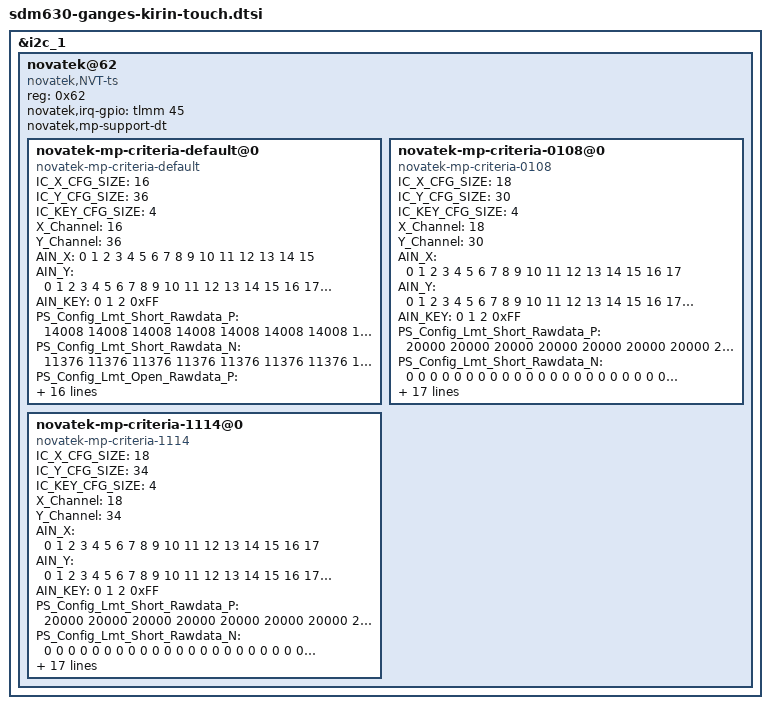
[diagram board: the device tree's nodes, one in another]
/* arch/arm64/boot/dts/somc/somc-ganges-touch.dtsi
 *
 * This program is free software; you can redistribute it and/or modify
 * it under the terms of the GNU General Public License version 2 and
 * only version 2 as published by the Free Software Foundation.
 *
 * This program is distributed in the hope that it will be useful,
 * but WITHOUT ANY WARRANTY; without even the implied warranty of
 * MERCHANTABILITY or FITNESS FOR A PARTICULAR PURPOSE.  See the
 * GNU General Public License for more details.
 */

&i2c_1 {
	status = "okay";

	novatek@62 {
		compatible = "novatek,NVT-ts";
		reg = <0x62>;
		status = "ok";

		/* vdd-supply = <&pm8994_lvs2>;    //VDDIO */
		/* avdd-supply = <&pm8994_l22>;    //VDD */

		/* novatek,reset-gpio = <&tlmm 53 0x00>; */
		novatek,irq-gpio = <&tlmm 45 0x2002>;

		/* MP */
		novatek,mp-support-dt;

		novatek-mp-criteria-default@0 {
			#address-cells = <1>;
			#size-cells = <0>;
			compatible = "novatek-mp-criteria-default";

			/* MP Config */
			IC_X_CFG_SIZE = <16>;
			IC_Y_CFG_SIZE = <36>;
			IC_KEY_CFG_SIZE = <4>;
			X_Channel = <16>;
			Y_Channel = <36>;
			AIN_X = <0 1 2 3 4 5 6 7 8 9 10 11 12 13 14 15>;
			AIN_Y = <0 1 2 3 4 5 6 7 8 9 10 11 12 13 14 15 16 17 18
				 19 20 21 22 23 24 25 26 27 28 29 30 31 32 33 34 35>;
			AIN_KEY = <0 1 2 0xFF>;

			/* MP Criteria */
			PS_Config_Lmt_Short_Rawdata_P = <
				14008 14008 14008 14008 14008 14008 14008 14008 14008 14008 14008 14008 14008 14008 14008 14008
				14008 14008 14008 14008 14008 14008 14008 14008 14008 14008 14008 14008 14008 14008 14008 14008
				14008 14008 14008 14008 14008 14008 14008 14008 14008 14008 14008 14008 14008 14008 14008 14008
				14008 14008 14008 14008 14008 14008 14008 14008 14008 14008 14008 14008 14008 14008 14008 14008
				14008 14008 14008 14008 14008 14008 14008 14008 14008 14008 14008 14008 14008 14008 14008 14008
				14008 14008 14008 14008 14008 14008 14008 14008 14008 14008 14008 14008 14008 14008 14008 14008
				14008 14008 14008 14008 14008 14008 14008 14008 14008 14008 14008 14008 14008 14008 14008 14008
				14008 14008 14008 14008 14008 14008 14008 14008 14008 14008 14008 14008 14008 14008 14008 14008
				14008 14008 14008 14008 14008 14008 14008 14008 14008 14008 14008 14008 14008 14008 14008 14008
				14008 14008 14008 14008 14008 14008 14008 14008 14008 14008 14008 14008 14008 14008 14008 14008
				14008 14008 14008 14008 14008 14008 14008 14008 14008 14008 14008 14008 14008 14008 14008 14008
				14008 14008 14008 14008 14008 14008 14008 14008 14008 14008 14008 14008 14008 14008 14008 14008
				14008 14008 14008 14008 14008 14008 14008 14008 14008 14008 14008 14008 14008 14008 14008 14008
				14008 14008 14008 14008 14008 14008 14008 14008 14008 14008 14008 14008 14008 14008 14008 14008
				14008 14008 14008 14008 14008 14008 14008 14008 14008 14008 14008 14008 14008 14008 14008 14008
				14008 14008 14008 14008 14008 14008 14008 14008 14008 14008 14008 14008 14008 14008 14008 14008
				14008 14008 14008 14008 14008 14008 14008 14008 14008 14008 14008 14008 14008 14008 14008 14008
				14008 14008 14008 14008 14008 14008 14008 14008 14008 14008 14008 14008 14008 14008 14008 14008
				14008 14008 14008 14008 14008 14008 14008 14008 14008 14008 14008 14008 14008 14008 14008 14008
				14008 14008 14008 14008 14008 14008 14008 14008 14008 14008 14008 14008 14008 14008 14008 14008
				14008 14008 14008 14008 14008 14008 14008 14008 14008 14008 14008 14008 14008 14008 14008 14008
				14008 14008 14008 14008 14008 14008 14008 14008 14008 14008 14008 14008 14008 14008 14008 14008
				14008 14008 14008 14008 14008 14008 14008 14008 14008 14008 14008 14008 14008 14008 14008 14008
				14008 14008 14008 14008 14008 14008 14008 14008 14008 14008 14008 14008 14008 14008 14008 14008
				14008 14008 14008 14008 14008 14008 14008 14008 14008 14008 14008 14008 14008 14008 14008 14008
				14008 14008 14008 14008 14008 14008 14008 14008 14008 14008 14008 14008 14008 14008 14008 14008
				14008 14008 14008 14008 14008 14008 14008 14008 14008 14008 14008 14008 14008 14008 14008 14008
				14008 14008 14008 14008 14008 14008 14008 14008 14008 14008 14008 14008 14008 14008 14008 14008
				14008 14008 14008 14008 14008 14008 14008 14008 14008 14008 14008 14008 14008 14008 14008 14008
				14008 14008 14008 14008 14008 14008 14008 14008 14008 14008 14008 14008 14008 14008 14008 14008
				14008 14008 14008 14008 14008 14008 14008 14008 14008 14008 14008 14008 14008 14008 14008 14008
				14008 14008 14008 14008 14008 14008 14008 14008 14008 14008 14008 14008 14008 14008 14008 14008
				14008 14008 14008 14008 14008 14008 14008 14008 14008 14008 14008 14008 14008 14008 14008 14008
				14008 14008 14008 14008 14008 14008 14008 14008 14008 14008 14008 14008 14008 14008 14008 14008
				14008 14008 14008 14008 14008 14008 14008 14008 14008 14008 14008 14008 14008 14008 14008 14008
				14008 14008 14008 14008 14008 14008 14008 14008 14008 14008 14008 14008 14008 14008 14008 14008
				>;

			PS_Config_Lmt_Short_Rawdata_N = <
				11376 11376 11376 11376 11376 11376 11376 11376 11376 11376 11376 11376 11376 11376 11376 11376
				11376 11376 11376 11376 11376 11376 11376 11376 11376 11376 11376 11376 11376 11376 11376 11376
				11376 11376 11376 11376 11376 11376 11376 11376 11376 11376 11376 11376 11376 11376 11376 11376
				11376 11376 11376 11376 11376 11376 11376 11376 11376 11376 11376 11376 11376 11376 11376 11376
				11376 11376 11376 11376 11376 11376 11376 11376 11376 11376 11376 11376 11376 11376 11376 11376
				11376 11376 11376 11376 11376 11376 11376 11376 11376 11376 11376 11376 11376 11376 11376 11376
				11376 11376 11376 11376 11376 11376 11376 11376 11376 11376 11376 11376 11376 11376 11376 11376
				11376 11376 11376 11376 11376 11376 11376 11376 11376 11376 11376 11376 11376 11376 11376 11376
				11376 11376 11376 11376 11376 11376 11376 11376 11376 11376 11376 11376 11376 11376 11376 11376
				11376 11376 11376 11376 11376 11376 11376 11376 11376 11376 11376 11376 11376 11376 11376 11376
				11376 11376 11376 11376 11376 11376 11376 11376 11376 11376 11376 11376 11376 11376 11376 11376
				11376 11376 11376 11376 11376 11376 11376 11376 11376 11376 11376 11376 11376 11376 11376 11376
				11376 11376 11376 11376 11376 11376 11376 11376 11376 11376 11376 11376 11376 11376 11376 11376
				11376 11376 11376 11376 11376 11376 11376 11376 11376 11376 11376 11376 11376 11376 11376 11376
				11376 11376 11376 11376 11376 11376 11376 11376 11376 11376 11376 11376 11376 11376 11376 11376
				11376 11376 11376 11376 11376 11376 11376 11376 11376 11376 11376 11376 11376 11376 11376 11376
				11376 11376 11376 11376 11376 11376 11376 11376 11376 11376 11376 11376 11376 11376 11376 11376
				11376 11376 11376 11376 11376 11376 11376 11376 11376 11376 11376 11376 11376 11376 11376 11376
				11376 11376 11376 11376 11376 11376 11376 11376 11376 11376 11376 11376 11376 11376 11376 11376
				11376 11376 11376 11376 11376 11376 11376 11376 11376 11376 11376 11376 11376 11376 11376 11376
				11376 11376 11376 11376 11376 11376 11376 11376 11376 11376 11376 11376 11376 11376 11376 11376
				11376 11376 11376 11376 11376 11376 11376 11376 11376 11376 11376 11376 11376 11376 11376 11376
				11376 11376 11376 11376 11376 11376 11376 11376 11376 11376 11376 11376 11376 11376 11376 11376
				11376 11376 11376 11376 11376 11376 11376 11376 11376 11376 11376 11376 11376 11376 11376 11376
				11376 11376 11376 11376 11376 11376 11376 11376 11376 11376 11376 11376 11376 11376 11376 11376
				11376 11376 11376 11376 11376 11376 11376 11376 11376 11376 11376 11376 11376 11376 11376 11376
				11376 11376 11376 11376 11376 11376 11376 11376 11376 11376 11376 11376 11376 11376 11376 11376
				11376 11376 11376 11376 11376 11376 11376 11376 11376 11376 11376 11376 11376 11376 11376 11376
				11376 11376 11376 11376 11376 11376 11376 11376 11376 11376 11376 11376 11376 11376 11376 11376
				11376 11376 11376 11376 11376 11376 11376 11376 11376 11376 11376 11376 11376 11376 11376 11376
				11376 11376 11376 11376 11376 11376 11376 11376 11376 11376 11376 11376 11376 11376 11376 11376
				11376 11376 11376 11376 11376 11376 11376 11376 11376 11376 11376 11376 11376 11376 11376 11376
				11376 11376 11376 11376 11376 11376 11376 11376 11376 11376 11376 11376 11376 11376 11376 11376
				11376 11376 11376 11376 11376 11376 11376 11376 11376 11376 11376 11376 11376 11376 11376 11376
				11376 11376 11376 11376 11376 11376 11376 11376 11376 11376 11376 11376 11376 11376 11376 11376
				11376 11376 11376 11376 11376 11376 11376 11376 11376 11376 11376 11376 11376 11376 11376 11376
				>;

			PS_Config_Lmt_Open_Rawdata_P = <
				2522 2594 2845 2823 2801 2718 2667 2769 2762 2668 2731 2816 2840 2869 2623 2508
				2532 2497 2746 2724 2703 2615 2559 2653 2637 2550 2615 2707 2728 2757 2514 2504
				2565 2519 2769 2747 2726 2641 2581 2679 2682 2588 2657 2748 2768 2795 2553 2558
				2619 2566 2816 2794 2777 2691 2630 2728 2722 2628 2699 2788 2805 2830 2588 2599
				2670 2610 2867 2844 2831 2744 2682 2783 2773 2678 2748 2835 2851 2877 2628 2646
				2728 2662 2911 2889 2877 2794 2732 2837 2819 2718 2788 2874 2886 2911 2673 2693
				2764 2699 2951 2929 2920 2835 2768 2870 2874 2784 2856 2943 2953 2978 2732 2751
				2917 2841 3098 3077 3071 2993 2926 3029 3023 2938 3004 3084 3089 3117 2871 2899
				2968 2888 3147 3125 3122 3047 2983 3078 3076 2986 3051 3129 3131 3161 2914 2949
				3022 2942 3198 3175 3174 3106 3040 3128 3111 3031 3102 3171 3175 3204 2958 2993
				3059 2973 3233 3208 3208 3142 3074 3153 3157 3089 3160 3226 3233 3259 3015 3049
				3110 3018 3274 3252 3249 3182 3117 3187 3182 3122 3191 3256 3265 3291 3048 3087
				3158 3066 3321 3300 3296 3233 3167 3223 3214 3165 3236 3299 3309 3331 3082 3132
				3212 3116 3372 3350 3345 3283 3215 3267 3247 3201 3276 3338 3349 3368 3122 3171
				3241 3146 3401 3378 3372 3313 3241 3288 3287 3248 3323 3385 3398 3418 3169 3219
				3280 3186 3438 3419 3412 3354 3284 3325 3316 3283 3356 3415 3429 3450 3202 3248
				3313 3223 3477 3459 3454 3394 3325 3364 3349 3321 3394 3451 3465 3485 3233 3287
				3353 3263 3519 3498 3492 3437 3368 3403 3376 3354 3425 3481 3492 3513 3260 3316
				3437 3329 3576 3545 3531 3469 3394 3409 3465 3443 3507 3552 3554 3565 3306 3354
				3480 3369 3612 3582 3568 3510 3434 3455 3503 3480 3547 3590 3590 3603 3342 3397
				3519 3404 3650 3618 3603 3547 3472 3478 3525 3516 3583 3628 3629 3641 3378 3438
				3560 3437 3683 3651 3637 3585 3506 3505 3546 3541 3612 3655 3657 3669 3405 3476
				3582 3456 3705 3672 3658 3604 3525 3521 3567 3564 3640 3681 3687 3699 3434 3512
				3690 3485 3734 3702 3684 3630 3550 3543 3571 3582 3655 3698 3703 3714 3451 3661
				3684 3503 3752 3723 3703 3652 3570 3552 3586 3605 3679 3717 3723 3737 3473 3612
				3621 3532 3783 3750 3735 3685 3603 3582 3597 3622 3699 3737 3741 3757 3494 3538
				3621 3538 3792 3761 3745 3695 3618 3582 3611 3644 3721 3759 3763 3781 3519 3553
				3633 3557 3808 3778 3761 3716 3634 3594 3610 3651 3726 3760 3767 3785 3530 3560
				3640 3565 3817 3789 3770 3726 3643 3599 3618 3662 3739 3772 3781 3799 3545 3571
				3648 3579 3828 3803 3786 3739 3657 3607 3616 3666 3743 3775 3785 3803 3553 3574
				3651 3583 3832 3807 3788 3746 3661 3603 3616 3674 3754 3783 3796 3814 3567 3586
				3657 3592 3837 3817 3796 3756 3670 3610 3616 3681 3761 3789 3803 3819 3572 3583
				3652 3590 3835 3818 3796 3761 3674 3610 3621 3691 3771 3800 3811 3829 3583 3589
				3655 3596 3837 3822 3806 3770 3684 3615 3616 3688 3770 3796 3806 3822 3581 3581
				3648 3603 3844 3833 3814 3781 3698 3623 3630 3708 3788 3811 3821 3836 3597 3586
				3652 3770 4014 4006 3985 3955 3876 3796 3793 3873 3946 3970 3981 3997 3759 3575
				>;

			PS_Config_Lmt_Open_Rawdata_N = <
				1133 1165 1278 1268 1258 1221 1198 1244 1241 1199 1226 1265 1275 1288 1178 1127
				1137 1122 1233 1223 1214 1174 1150 1192 1184 1145 1174 1216 1225 1238 1129 1125
				1152 1132 1244 1234 1225 1186 1160 1204 1205 1163 1194 1235 1243 1256 1147 1149
				1176 1153 1265 1255 1248 1209 1181 1225 1223 1181 1212 1253 1260 1271 1163 1168
				1199 1173 1288 1277 1272 1233 1205 1250 1246 1203 1235 1274 1280 1292 1181 1189
				1225 1195 1308 1298 1292 1255 1227 1274 1266 1221 1253 1291 1297 1308 1200 1210
				1241 1212 1326 1316 1311 1274 1243 1289 1291 1251 1283 1322 1326 1337 1227 1236
				1310 1276 1391 1382 1380 1344 1315 1360 1358 1319 1349 1385 1388 1400 1290 1302
				1333 1297 1414 1404 1403 1368 1340 1383 1381 1341 1370 1406 1406 1420 1309 1324
				1357 1321 1437 1426 1426 1395 1365 1405 1398 1362 1393 1424 1426 1439 1329 1344
				1374 1336 1452 1441 1441 1411 1381 1416 1418 1388 1419 1449 1452 1464 1354 1370
				1397 1355 1471 1461 1460 1429 1400 1432 1429 1403 1434 1463 1466 1478 1369 1386
				1419 1377 1492 1483 1481 1452 1422 1448 1443 1422 1453 1482 1486 1496 1385 1407
				1443 1399 1515 1505 1502 1474 1444 1468 1458 1438 1471 1499 1504 1513 1403 1424
				1456 1413 1528 1517 1515 1488 1456 1477 1476 1459 1492 1520 1527 1535 1424 1446
				1473 1431 1545 1536 1533 1507 1475 1494 1489 1474 1507 1534 1540 1550 1439 1459
				1488 1448 1562 1554 1551 1525 1494 1511 1504 1492 1525 1550 1556 1566 1452 1476
				1506 1466 1581 1571 1569 1544 1513 1528 1517 1507 1538 1564 1569 1578 1465 1489
				1544 1496 1607 1592 1586 1558 1525 1532 1556 1546 1576 1595 1597 1602 1485 1507
				1563 1514 1623 1609 1603 1577 1543 1552 1574 1563 1594 1613 1613 1618 1501 1526
				1581 1529 1639 1625 1618 1594 1559 1563 1584 1579 1610 1629 1630 1636 1517 1545
				1599 1544 1654 1640 1634 1610 1575 1574 1593 1590 1623 1642 1643 1648 1530 1561
				1609 1553 1664 1649 1643 1619 1584 1582 1602 1601 1635 1654 1656 1662 1543 1577
				1657 1566 1677 1663 1655 1631 1595 1592 1604 1609 1642 1661 1664 1669 1550 1644
				1655 1574 1685 1672 1664 1641 1603 1595 1611 1620 1652 1670 1672 1678 1560 1623
				1626 1587 1700 1685 1678 1656 1618 1609 1616 1627 1662 1678 1680 1688 1569 1589
				1626 1589 1703 1690 1682 1660 1625 1609 1622 1637 1672 1688 1690 1698 1581 1596
				1632 1598 1711 1697 1690 1669 1633 1615 1621 1640 1674 1689 1692 1700 1585 1599
				1635 1602 1714 1702 1693 1674 1636 1616 1625 1645 1680 1695 1698 1706 1592 1604
				1639 1608 1719 1708 1701 1680 1643 1620 1625 1647 1682 1696 1700 1708 1596 1605
				1640 1610 1721 1710 1701 1683 1644 1618 1625 1651 1687 1700 1705 1713 1602 1611
				1643 1613 1724 1714 1705 1687 1649 1621 1625 1654 1690 1702 1708 1716 1605 1610
				1641 1613 1722 1715 1705 1690 1651 1621 1626 1658 1694 1707 1712 1720 1610 1612
				1642 1615 1724 1717 1709 1693 1655 1624 1625 1657 1693 1705 1709 1717 1608 1608
				1639 1618 1727 1722 1713 1698 1661 1628 1631 1665 1701 1712 1716 1723 1616 1611
				1641 1693 1803 1799 1790 1776 1741 1705 1704 1740 1773 1783 1788 1796 1688 1606
				>;

			PS_Config_Lmt_FW_Rawdata_P = <
				1600 1600 1600 1600 1600 1600 1600 1600 1600 1600 1600 1600 1600 1600 1600 1600
				1600 1600 1600 1600 1600 1600 1600 1600 1600 1600 1600 1600 1600 1600 1600 1600
				1600 1600 1600 1600 1600 1600 1600 1600 1600 1600 1600 1600 1600 1600 1600 1600
				1600 1600 1600 1600 1600 1600 1600 1600 1600 1600 1600 1600 1600 1600 1600 1600
				1600 1600 1600 1600 1600 1600 1600 1600 1600 1600 1600 1600 1600 1600 1600 1600
				1600 1600 1600 1600 1600 1600 1600 1600 1600 1600 1600 1600 1600 1600 1600 1600
				1600 1600 1600 1600 1600 1600 1600 1600 1600 1600 1600 1600 1600 1600 1600 1600
				1600 1600 1600 1600 1600 1600 1600 1600 1600 1600 1600 1600 1600 1600 1600 1600
				1600 1600 1600 1600 1600 1600 1600 1600 1600 1600 1600 1600 1600 1600 1600 1600
				1600 1600 1600 1600 1600 1600 1600 1600 1600 1600 1600 1600 1600 1600 1600 1600
				1600 1600 1600 1600 1600 1600 1600 1600 1600 1600 1600 1600 1600 1600 1600 1600
				1600 1600 1600 1600 1600 1600 1600 1600 1600 1600 1600 1600 1600 1600 1600 1600
				1600 1600 1600 1600 1600 1600 1600 1600 1600 1600 1600 1600 1600 1600 1600 1600
				1600 1600 1600 1600 1600 1600 1600 1600 1600 1600 1600 1600 1600 1600 1600 1600
				1600 1600 1600 1600 1600 1600 1600 1600 1600 1600 1600 1600 1600 1600 1600 1600
				1600 1600 1600 1600 1600 1600 1600 1600 1600 1600 1600 1600 1600 1600 1600 1600
				1600 1600 1600 1600 1600 1600 1600 1600 1600 1600 1600 1600 1600 1600 1600 1600
				1600 1600 1600 1600 1600 1600 1600 1600 1600 1600 1600 1600 1600 1600 1600 1600
				1600 1600 1600 1600 1600 1600 1600 1600 1600 1600 1600 1600 1600 1600 1600 1600
				1600 1600 1600 1600 1600 1600 1600 1600 1600 1600 1600 1600 1600 1600 1600 1600
				1600 1600 1600 1600 1600 1600 1600 1600 1600 1600 1600 1600 1600 1600 1600 1600
				1600 1600 1600 1600 1600 1600 1600 1600 1600 1600 1600 1600 1600 1600 1600 1600
				1600 1600 1600 1600 1600 1600 1600 1600 1600 1600 1600 1600 1600 1600 1600 1600
				1600 1600 1600 1600 1600 1600 1600 1600 1600 1600 1600 1600 1600 1600 1600 1600
				1600 1600 1600 1600 1600 1600 1600 1600 1600 1600 1600 1600 1600 1600 1600 1600
				1600 1600 1600 1600 1600 1600 1600 1600 1600 1600 1600 1600 1600 1600 1600 1600
				1600 1600 1600 1600 1600 1600 1600 1600 1600 1600 1600 1600 1600 1600 1600 1600
				1600 1600 1600 1600 1600 1600 1600 1600 1600 1600 1600 1600 1600 1600 1600 1600
				1600 1600 1600 1600 1600 1600 1600 1600 1600 1600 1600 1600 1600 1600 1600 1600
				1600 1600 1600 1600 1600 1600 1600 1600 1600 1600 1600 1600 1600 1600 1600 1600
				1600 1600 1600 1600 1600 1600 1600 1600 1600 1600 1600 1600 1600 1600 1600 1600
				1600 1600 1600 1600 1600 1600 1600 1600 1600 1600 1600 1600 1600 1600 1600 1600
				1600 1600 1600 1600 1600 1600 1600 1600 1600 1600 1600 1600 1600 1600 1600 1600
				1600 1600 1600 1600 1600 1600 1600 1600 1600 1600 1600 1600 1600 1600 1600 1600
				1600 1600 1600 1600 1600 1600 1600 1600 1600 1600 1600 1600 1600 1600 1600 1600
				1600 1600 1600 1600 1600 1600 1600 1600 1600 1600 1600 1600 1600 1600 1600 1600
				>;

			PS_Config_Lmt_FW_Rawdata_N = <
				800 800 800 800 800 800 800 800 800 800 800 800 800 800 800 800
				800 800 800 800 800 800 800 800 800 800 800 800 800 800 800 800
				800 800 800 800 800 800 800 800 800 800 800 800 800 800 800 800
				800 800 800 800 800 800 800 800 800 800 800 800 800 800 800 800
				800 800 800 800 800 800 800 800 800 800 800 800 800 800 800 800
				800 800 800 800 800 800 800 800 800 800 800 800 800 800 800 800
				800 800 800 800 800 800 800 800 800 800 800 800 800 800 800 800
				800 800 800 800 800 800 800 800 800 800 800 800 800 800 800 800
				800 800 800 800 800 800 800 800 800 800 800 800 800 800 800 800
				800 800 800 800 800 800 800 800 800 800 800 800 800 800 800 800
				800 800 800 800 800 800 800 800 800 800 800 800 800 800 800 800
				800 800 800 800 800 800 800 800 800 800 800 800 800 800 800 800
				800 800 800 800 800 800 800 800 800 800 800 800 800 800 800 800
				800 800 800 800 800 800 800 800 800 800 800 800 800 800 800 800
				800 800 800 800 800 800 800 800 800 800 800 800 800 800 800 800
				800 800 800 800 800 800 800 800 800 800 800 800 800 800 800 800
				800 800 800 800 800 800 800 800 800 800 800 800 800 800 800 800
				800 800 800 800 800 800 800 800 800 800 800 800 800 800 800 800
				800 800 800 800 800 800 800 800 800 800 800 800 800 800 800 800
				800 800 800 800 800 800 800 800 800 800 800 800 800 800 800 800
				800 800 800 800 800 800 800 800 800 800 800 800 800 800 800 800
				800 800 800 800 800 800 800 800 800 800 800 800 800 800 800 800
				800 800 800 800 800 800 800 800 800 800 800 800 800 800 800 800
				800 800 800 800 800 800 800 800 800 800 800 800 800 800 800 800
				800 800 800 800 800 800 800 800 800 800 800 800 800 800 800 800
				800 800 800 800 800 800 800 800 800 800 800 800 800 800 800 800
				800 800 800 800 800 800 800 800 800 800 800 800 800 800 800 800
				800 800 800 800 800 800 800 800 800 800 800 800 800 800 800 800
				800 800 800 800 800 800 800 800 800 800 800 800 800 800 800 800
				800 800 800 800 800 800 800 800 800 800 800 800 800 800 800 800
				800 800 800 800 800 800 800 800 800 800 800 800 800 800 800 800
				800 800 800 800 800 800 800 800 800 800 800 800 800 800 800 800
				800 800 800 800 800 800 800 800 800 800 800 800 800 800 800 800
				800 800 800 800 800 800 800 800 800 800 800 800 800 800 800 800
				800 800 800 800 800 800 800 800 800 800 800 800 800 800 800 800
				800 800 800 800 800 800 800 800 800 800 800 800 800 800 800 800
				>;

			PS_Config_Lmt_FW_CC_P = <
				126 122 122 122 121 120 124 125 124 124 120 121 122 122 124 126
				129 125 124 124 122 121 124 125 122 122 120 121 122 122 124 124
				125 122 122 121 120 120 121 122 126 125 122 124 125 126 126 128
				128 124 124 122 121 121 121 124 124 122 121 122 124 124 125 125
				128 122 124 122 121 121 121 124 124 122 121 122 124 125 125 126
				129 125 125 124 122 121 122 125 122 120 120 121 122 124 124 125
				126 122 122 121 120 118 120 121 125 122 122 124 125 128 126 128
				129 125 125 124 122 121 122 124 124 122 121 122 124 125 126 128
				129 125 125 124 122 121 121 124 125 122 122 122 124 126 126 129
				132 126 126 125 124 122 122 126 122 121 121 121 122 124 124 126
				129 124 124 122 121 120 121 122 125 124 122 124 125 128 128 130
				130 125 124 122 121 121 121 122 121 121 120 121 122 124 125 128
				130 125 125 124 121 121 121 121 121 121 120 121 122 124 124 128
				133 128 128 126 124 122 124 124 120 120 120 121 122 122 122 128
				130 124 124 122 121 120 120 121 121 122 122 122 125 126 126 130
				132 125 125 124 122 121 121 122 120 120 120 121 122 124 124 129
				132 125 125 124 122 121 121 122 121 120 120 121 124 124 124 129
				133 126 126 125 124 122 122 124 120 118 118 120 121 122 122 128
				130 124 124 124 121 120 120 121 121 121 121 122 124 125 125 129
				133 125 125 124 122 121 121 122 121 120 120 121 122 124 124 128
				132 125 125 125 122 121 121 122 121 120 120 121 124 124 124 129
				134 128 128 126 124 122 122 124 120 118 118 120 121 122 122 128
				132 125 125 124 122 120 121 122 121 121 121 122 125 125 126 130
				133 126 126 125 124 121 121 121 118 118 118 121 122 122 124 129
				125 126 126 126 122 121 121 121 118 118 118 121 122 122 124 125
				128 129 128 128 126 124 122 122 117 118 118 120 121 122 122 126
				126 126 126 125 124 121 121 120 120 120 121 122 124 125 125 129
				128 128 128 126 125 122 122 121 117 118 118 121 122 124 124 128
				126 128 128 126 124 122 122 121 117 118 118 121 122 124 124 128
				128 129 129 128 126 124 122 122 116 117 117 120 121 122 122 126
				125 128 126 125 124 121 121 120 117 118 120 122 122 124 125 129
				128 129 128 126 125 122 122 121 117 117 118 120 122 122 124 126
				126 128 128 126 125 122 121 121 117 117 120 121 122 124 125 128
				129 130 129 128 126 124 122 122 116 117 118 120 121 122 124 126
				126 128 126 125 124 122 121 120 118 118 120 122 122 124 126 128
				128 129 128 126 125 124 121 122 116 116 118 120 121 122 124 126
				>;

			PS_Config_Lmt_FW_CC_N = <
				65 63 63 63 62 61 63 64 63 63 61 62 63 63 63 65
				66 64 63 63 63 62 63 64 63 63 61 62 63 63 63 63
				64 63 63 62 61 61 62 63 65 64 63 63 64 65 65 65
				65 63 63 63 62 62 62 63 63 63 62 63 63 63 64 64
				65 63 63 63 62 62 62 63 63 63 62 63 63 64 64 65
				66 64 64 63 63 62 63 64 63 61 61 62 63 63 63 64
				65 63 63 62 61 61 61 62 64 63 63 63 64 65 65 65
				66 64 64 63 63 62 63 63 63 63 62 63 63 64 65 65
				66 64 64 63 63 62 62 63 64 63 63 63 63 65 65 66
				68 65 65 64 63 63 63 65 63 62 62 62 63 63 63 65
				66 63 63 63 62 61 62 63 64 63 63 63 64 65 65 67
				67 64 63 63 62 62 62 63 62 62 61 62 63 63 64 65
				67 64 64 63 62 62 62 62 62 62 61 62 63 63 63 65
				68 65 65 65 63 63 63 63 61 61 61 62 63 63 63 65
				67 63 63 63 62 61 61 62 62 63 63 63 64 65 65 67
				68 64 64 63 63 62 62 63 61 61 61 62 63 63 63 66
				68 64 64 63 63 62 62 63 62 61 61 62 63 63 63 66
				68 65 65 64 63 63 63 63 61 61 61 61 62 63 63 65
				67 63 63 63 62 61 61 62 62 62 62 63 63 64 64 66
				68 64 64 63 63 62 62 63 62 61 61 62 63 63 63 65
				68 64 64 64 63 62 62 63 62 61 61 62 63 63 63 66
				69 65 65 65 63 63 63 63 61 61 61 61 62 63 63 65
				68 64 64 63 63 61 62 63 62 62 62 63 64 64 65 67
				68 65 65 64 63 62 62 62 61 61 61 62 63 63 63 66
				64 65 65 65 63 62 62 62 61 61 61 62 63 63 63 64
				65 66 65 65 65 63 63 63 60 61 61 61 62 63 63 65
				65 65 65 64 63 62 62 61 61 61 62 63 63 64 64 66
				65 65 65 65 64 63 63 62 60 61 61 62 63 63 63 65
				65 65 65 65 63 63 63 62 60 61 61 62 63 63 63 65
				65 66 66 65 65 63 63 63 59 60 60 61 62 63 63 65
				64 65 65 64 63 62 62 61 60 61 61 63 63 63 64 66
				65 66 65 65 64 63 63 62 60 60 61 61 63 63 63 65
				65 65 65 65 64 63 62 62 60 60 61 62 63 63 64 65
				66 67 66 65 65 63 63 63 59 60 61 61 62 63 63 65
				65 65 65 64 63 63 62 61 61 61 61 63 63 63 65 65
				65 66 65 65 64 63 62 63 59 59 61 61 62 63 63 65
				>;

			PS_Config_Lmt_FW_Diff_P = <
				50 50 50 50 50 50 50 50 50 50 50 50 50 50 50 50
				50 50 50 50 50 50 50 50 50 50 50 50 50 50 50 50
				50 50 50 50 50 50 50 50 50 50 50 50 50 50 50 50
				50 50 50 50 50 50 50 50 50 50 50 50 50 50 50 50
				50 50 50 50 50 50 50 50 50 50 50 50 50 50 50 50
				50 50 50 50 50 50 50 50 50 50 50 50 50 50 50 50
				50 50 50 50 50 50 50 50 50 50 50 50 50 50 50 50
				50 50 50 50 50 50 50 50 50 50 50 50 50 50 50 50
				50 50 50 50 50 50 50 50 50 50 50 50 50 50 50 50
				50 50 50 50 50 50 50 50 50 50 50 50 50 50 50 50
				50 50 50 50 50 50 50 50 50 50 50 50 50 50 50 50
				50 50 50 50 50 50 50 50 50 50 50 50 50 50 50 50
				50 50 50 50 50 50 50 50 50 50 50 50 50 50 50 50
				50 50 50 50 50 50 50 50 50 50 50 50 50 50 50 50
				50 50 50 50 50 50 50 50 50 50 50 50 50 50 50 50
				50 50 50 50 50 50 50 50 50 50 50 50 50 50 50 50
				50 50 50 50 50 50 50 50 50 50 50 50 50 50 50 50
				50 50 50 50 50 50 50 50 50 50 50 50 50 50 50 50
				50 50 50 50 50 50 50 50 50 50 50 50 50 50 50 50
				50 50 50 50 50 50 50 50 50 50 50 50 50 50 50 50
				50 50 50 50 50 50 50 50 50 50 50 50 50 50 50 50
				50 50 50 50 50 50 50 50 50 50 50 50 50 50 50 50
				50 50 50 50 50 50 50 50 50 50 50 50 50 50 50 50
				50 50 50 50 50 50 50 50 50 50 50 50 50 50 50 50
				50 50 50 50 50 50 50 50 50 50 50 50 50 50 50 50
				50 50 50 50 50 50 50 50 50 50 50 50 50 50 50 50
				50 50 50 50 50 50 50 50 50 50 50 50 50 50 50 50
				50 50 50 50 50 50 50 50 50 50 50 50 50 50 50 50
				50 50 50 50 50 50 50 50 50 50 50 50 50 50 50 50
				50 50 50 50 50 50 50 50 50 50 50 50 50 50 50 50
				50 50 50 50 50 50 50 50 50 50 50 50 50 50 50 50
				50 50 50 50 50 50 50 50 50 50 50 50 50 50 50 50
				50 50 50 50 50 50 50 50 50 50 50 50 50 50 50 50
				50 50 50 50 50 50 50 50 50 50 50 50 50 50 50 50
				50 50 50 50 50 50 50 50 50 50 50 50 50 50 50 50
				50 50 50 50 50 50 50 50 50 50 50 50 50 50 50 50
				>;

			PS_Config_Lmt_FW_Diff_N = <
				(-50) (-50) (-50) (-50) (-50) (-50) (-50) (-50) (-50) (-50) (-50) (-50) (-50) (-50) (-50) (-50)
				(-50) (-50) (-50) (-50) (-50) (-50) (-50) (-50) (-50) (-50) (-50) (-50) (-50) (-50) (-50) (-50)
				(-50) (-50) (-50) (-50) (-50) (-50) (-50) (-50) (-50) (-50) (-50) (-50) (-50) (-50) (-50) (-50)
				(-50) (-50) (-50) (-50) (-50) (-50) (-50) (-50) (-50) (-50) (-50) (-50) (-50) (-50) (-50) (-50)
				(-50) (-50) (-50) (-50) (-50) (-50) (-50) (-50) (-50) (-50) (-50) (-50) (-50) (-50) (-50) (-50)
				(-50) (-50) (-50) (-50) (-50) (-50) (-50) (-50) (-50) (-50) (-50) (-50) (-50) (-50) (-50) (-50)
				(-50) (-50) (-50) (-50) (-50) (-50) (-50) (-50) (-50) (-50) (-50) (-50) (-50) (-50) (-50) (-50)
				(-50) (-50) (-50) (-50) (-50) (-50) (-50) (-50) (-50) (-50) (-50) (-50) (-50) (-50) (-50) (-50)
				(-50) (-50) (-50) (-50) (-50) (-50) (-50) (-50) (-50) (-50) (-50) (-50) (-50) (-50) (-50) (-50)
				(-50) (-50) (-50) (-50) (-50) (-50) (-50) (-50) (-50) (-50) (-50) (-50) (-50) (-50) (-50) (-50)
				(-50) (-50) (-50) (-50) (-50) (-50) (-50) (-50) (-50) (-50) (-50) (-50) (-50) (-50) (-50) (-50)
				(-50) (-50) (-50) (-50) (-50) (-50) (-50) (-50) (-50) (-50) (-50) (-50) (-50) (-50) (-50) (-50)
				(-50) (-50) (-50) (-50) (-50) (-50) (-50) (-50) (-50) (-50) (-50) (-50) (-50) (-50) (-50) (-50)
				(-50) (-50) (-50) (-50) (-50) (-50) (-50) (-50) (-50) (-50) (-50) (-50) (-50) (-50) (-50) (-50)
				(-50) (-50) (-50) (-50) (-50) (-50) (-50) (-50) (-50) (-50) (-50) (-50) (-50) (-50) (-50) (-50)
				(-50) (-50) (-50) (-50) (-50) (-50) (-50) (-50) (-50) (-50) (-50) (-50) (-50) (-50) (-50) (-50)
				(-50) (-50) (-50) (-50) (-50) (-50) (-50) (-50) (-50) (-50) (-50) (-50) (-50) (-50) (-50) (-50)
				(-50) (-50) (-50) (-50) (-50) (-50) (-50) (-50) (-50) (-50) (-50) (-50) (-50) (-50) (-50) (-50)
				(-50) (-50) (-50) (-50) (-50) (-50) (-50) (-50) (-50) (-50) (-50) (-50) (-50) (-50) (-50) (-50)
				(-50) (-50) (-50) (-50) (-50) (-50) (-50) (-50) (-50) (-50) (-50) (-50) (-50) (-50) (-50) (-50)
				(-50) (-50) (-50) (-50) (-50) (-50) (-50) (-50) (-50) (-50) (-50) (-50) (-50) (-50) (-50) (-50)
				(-50) (-50) (-50) (-50) (-50) (-50) (-50) (-50) (-50) (-50) (-50) (-50) (-50) (-50) (-50) (-50)
				(-50) (-50) (-50) (-50) (-50) (-50) (-50) (-50) (-50) (-50) (-50) (-50) (-50) (-50) (-50) (-50)
				(-50) (-50) (-50) (-50) (-50) (-50) (-50) (-50) (-50) (-50) (-50) (-50) (-50) (-50) (-50) (-50)
				(-50) (-50) (-50) (-50) (-50) (-50) (-50) (-50) (-50) (-50) (-50) (-50) (-50) (-50) (-50) (-50)
				(-50) (-50) (-50) (-50) (-50) (-50) (-50) (-50) (-50) (-50) (-50) (-50) (-50) (-50) (-50) (-50)
				(-50) (-50) (-50) (-50) (-50) (-50) (-50) (-50) (-50) (-50) (-50) (-50) (-50) (-50) (-50) (-50)
				(-50) (-50) (-50) (-50) (-50) (-50) (-50) (-50) (-50) (-50) (-50) (-50) (-50) (-50) (-50) (-50)
				(-50) (-50) (-50) (-50) (-50) (-50) (-50) (-50) (-50) (-50) (-50) (-50) (-50) (-50) (-50) (-50)
				(-50) (-50) (-50) (-50) (-50) (-50) (-50) (-50) (-50) (-50) (-50) (-50) (-50) (-50) (-50) (-50)
				(-50) (-50) (-50) (-50) (-50) (-50) (-50) (-50) (-50) (-50) (-50) (-50) (-50) (-50) (-50) (-50)
				(-50) (-50) (-50) (-50) (-50) (-50) (-50) (-50) (-50) (-50) (-50) (-50) (-50) (-50) (-50) (-50)
				(-50) (-50) (-50) (-50) (-50) (-50) (-50) (-50) (-50) (-50) (-50) (-50) (-50) (-50) (-50) (-50)
				(-50) (-50) (-50) (-50) (-50) (-50) (-50) (-50) (-50) (-50) (-50) (-50) (-50) (-50) (-50) (-50)
				(-50) (-50) (-50) (-50) (-50) (-50) (-50) (-50) (-50) (-50) (-50) (-50) (-50) (-50) (-50) (-50)
				(-50) (-50) (-50) (-50) (-50) (-50) (-50) (-50) (-50) (-50) (-50) (-50) (-50) (-50) (-50) (-50)
				>;

			PS_Config_Diff_Test_Frame = <50>;
		};

		/* SM13 currently */
		novatek-mp-criteria-0108@0 {
			#address-cells = <1>;
			#size-cells = <0>;
			compatible = "novatek-mp-criteria-0108";

			/* MP Config */
			IC_X_CFG_SIZE = <18>;
			IC_Y_CFG_SIZE = <30>;
			IC_KEY_CFG_SIZE = <4>;
			X_Channel = <18>;
			Y_Channel = <30>;
			AIN_X = <0 1 2 3 4 5 6 7 8 9 10 11 12 13 14 15 16 17>;
			AIN_Y = <0 1 2 3 4 5 6 7 8 9 10 11 12 13 14 15
					16 17 18 19 20 21 22 23 24 25 26 27 28 29>;
			AIN_KEY = <0 1 2 0xFF>;

			/* MP Criteria */
			PS_Config_Lmt_Short_Rawdata_P = <
				20000 20000 20000 20000 20000 20000 20000 20000 20000 20000 20000 20000 20000 20000 20000 20000 20000 20000
				20000 20000 20000 20000 20000 20000 20000 20000 20000 20000 20000 20000 20000 20000 20000 20000 20000 20000
				20000 20000 20000 20000 20000 20000 20000 20000 20000 20000 20000 20000 20000 20000 20000 20000 20000 20000
				20000 20000 20000 20000 20000 20000 20000 20000 20000 20000 20000 20000 20000 20000 20000 20000 20000 20000
				20000 20000 20000 20000 20000 20000 20000 20000 20000 20000 20000 20000 20000 20000 20000 20000 20000 20000
				20000 20000 20000 20000 20000 20000 20000 20000 20000 20000 20000 20000 20000 20000 20000 20000 20000 20000
				20000 20000 20000 20000 20000 20000 20000 20000 20000 20000 20000 20000 20000 20000 20000 20000 20000 20000
				20000 20000 20000 20000 20000 20000 20000 20000 20000 20000 20000 20000 20000 20000 20000 20000 20000 20000
				20000 20000 20000 20000 20000 20000 20000 20000 20000 20000 20000 20000 20000 20000 20000 20000 20000 20000
				20000 20000 20000 20000 20000 20000 20000 20000 20000 20000 20000 20000 20000 20000 20000 20000 20000 20000
				20000 20000 20000 20000 20000 20000 20000 20000 20000 20000 20000 20000 20000 20000 20000 20000 20000 20000
				20000 20000 20000 20000 20000 20000 20000 20000 20000 20000 20000 20000 20000 20000 20000 20000 20000 20000
				20000 20000 20000 20000 20000 20000 20000 20000 20000 20000 20000 20000 20000 20000 20000 20000 20000 20000
				20000 20000 20000 20000 20000 20000 20000 20000 20000 20000 20000 20000 20000 20000 20000 20000 20000 20000
				20000 20000 20000 20000 20000 20000 20000 20000 20000 20000 20000 20000 20000 20000 20000 20000 20000 20000
				20000 20000 20000 20000 20000 20000 20000 20000 20000 20000 20000 20000 20000 20000 20000 20000 20000 20000
				20000 20000 20000 20000 20000 20000 20000 20000 20000 20000 20000 20000 20000 20000 20000 20000 20000 20000
				20000 20000 20000 20000 20000 20000 20000 20000 20000 20000 20000 20000 20000 20000 20000 20000 20000 20000
				20000 20000 20000 20000 20000 20000 20000 20000 20000 20000 20000 20000 20000 20000 20000 20000 20000 20000
				20000 20000 20000 20000 20000 20000 20000 20000 20000 20000 20000 20000 20000 20000 20000 20000 20000 20000
				20000 20000 20000 20000 20000 20000 20000 20000 20000 20000 20000 20000 20000 20000 20000 20000 20000 20000
				20000 20000 20000 20000 20000 20000 20000 20000 20000 20000 20000 20000 20000 20000 20000 20000 20000 20000
				20000 20000 20000 20000 20000 20000 20000 20000 20000 20000 20000 20000 20000 20000 20000 20000 20000 20000
				20000 20000 20000 20000 20000 20000 20000 20000 20000 20000 20000 20000 20000 20000 20000 20000 20000 20000
				20000 20000 20000 20000 20000 20000 20000 20000 20000 20000 20000 20000 20000 20000 20000 20000 20000 20000
				20000 20000 20000 20000 20000 20000 20000 20000 20000 20000 20000 20000 20000 20000 20000 20000 20000 20000
				20000 20000 20000 20000 20000 20000 20000 20000 20000 20000 20000 20000 20000 20000 20000 20000 20000 20000
				20000 20000 20000 20000 20000 20000 20000 20000 20000 20000 20000 20000 20000 20000 20000 20000 20000 20000
				20000 20000 20000 20000 20000 20000 20000 20000 20000 20000 20000 20000 20000 20000 20000 20000 20000 20000
				20000 20000 20000 20000 20000 20000 20000 20000 20000 20000 20000 20000 20000 20000 20000 20000 20000 20000
				>;

			PS_Config_Lmt_Short_Rawdata_N = <
				0 0 0 0 0 0 0 0 0 0 0 0 0 0 0 0 0 0
				0 0 0 0 0 0 0 0 0 0 0 0 0 0 0 0 0 0
				0 0 0 0 0 0 0 0 0 0 0 0 0 0 0 0 0 0
				0 0 0 0 0 0 0 0 0 0 0 0 0 0 0 0 0 0
				0 0 0 0 0 0 0 0 0 0 0 0 0 0 0 0 0 0
				0 0 0 0 0 0 0 0 0 0 0 0 0 0 0 0 0 0
				0 0 0 0 0 0 0 0 0 0 0 0 0 0 0 0 0 0
				0 0 0 0 0 0 0 0 0 0 0 0 0 0 0 0 0 0
				0 0 0 0 0 0 0 0 0 0 0 0 0 0 0 0 0 0
				0 0 0 0 0 0 0 0 0 0 0 0 0 0 0 0 0 0
				0 0 0 0 0 0 0 0 0 0 0 0 0 0 0 0 0 0
				0 0 0 0 0 0 0 0 0 0 0 0 0 0 0 0 0 0
				0 0 0 0 0 0 0 0 0 0 0 0 0 0 0 0 0 0
				0 0 0 0 0 0 0 0 0 0 0 0 0 0 0 0 0 0
				0 0 0 0 0 0 0 0 0 0 0 0 0 0 0 0 0 0
				0 0 0 0 0 0 0 0 0 0 0 0 0 0 0 0 0 0
				0 0 0 0 0 0 0 0 0 0 0 0 0 0 0 0 0 0
				0 0 0 0 0 0 0 0 0 0 0 0 0 0 0 0 0 0
				0 0 0 0 0 0 0 0 0 0 0 0 0 0 0 0 0 0
				0 0 0 0 0 0 0 0 0 0 0 0 0 0 0 0 0 0
				0 0 0 0 0 0 0 0 0 0 0 0 0 0 0 0 0 0
				0 0 0 0 0 0 0 0 0 0 0 0 0 0 0 0 0 0
				0 0 0 0 0 0 0 0 0 0 0 0 0 0 0 0 0 0
				0 0 0 0 0 0 0 0 0 0 0 0 0 0 0 0 0 0
				0 0 0 0 0 0 0 0 0 0 0 0 0 0 0 0 0 0
				0 0 0 0 0 0 0 0 0 0 0 0 0 0 0 0 0 0
				0 0 0 0 0 0 0 0 0 0 0 0 0 0 0 0 0 0
				0 0 0 0 0 0 0 0 0 0 0 0 0 0 0 0 0 0
				0 0 0 0 0 0 0 0 0 0 0 0 0 0 0 0 0 0
				0 0 0 0 0 0 0 0 0 0 0 0 0 0 0 0 0 0
				>;

			PS_Config_Lmt_Open_Rawdata_P = <
				20000 20000 20000 20000 20000 20000 20000 20000 20000 20000 20000 20000 20000 20000 20000 20000 20000 20000
				20000 20000 20000 20000 20000 20000 20000 20000 20000 20000 20000 20000 20000 20000 20000 20000 20000 20000
				20000 20000 20000 20000 20000 20000 20000 20000 20000 20000 20000 20000 20000 20000 20000 20000 20000 20000
				20000 20000 20000 20000 20000 20000 20000 20000 20000 20000 20000 20000 20000 20000 20000 20000 20000 20000
				20000 20000 20000 20000 20000 20000 20000 20000 20000 20000 20000 20000 20000 20000 20000 20000 20000 20000
				20000 20000 20000 20000 20000 20000 20000 20000 20000 20000 20000 20000 20000 20000 20000 20000 20000 20000
				20000 20000 20000 20000 20000 20000 20000 20000 20000 20000 20000 20000 20000 20000 20000 20000 20000 20000
				20000 20000 20000 20000 20000 20000 20000 20000 20000 20000 20000 20000 20000 20000 20000 20000 20000 20000
				20000 20000 20000 20000 20000 20000 20000 20000 20000 20000 20000 20000 20000 20000 20000 20000 20000 20000
				20000 20000 20000 20000 20000 20000 20000 20000 20000 20000 20000 20000 20000 20000 20000 20000 20000 20000
				20000 20000 20000 20000 20000 20000 20000 20000 20000 20000 20000 20000 20000 20000 20000 20000 20000 20000
				20000 20000 20000 20000 20000 20000 20000 20000 20000 20000 20000 20000 20000 20000 20000 20000 20000 20000
				20000 20000 20000 20000 20000 20000 20000 20000 20000 20000 20000 20000 20000 20000 20000 20000 20000 20000
				20000 20000 20000 20000 20000 20000 20000 20000 20000 20000 20000 20000 20000 20000 20000 20000 20000 20000
				20000 20000 20000 20000 20000 20000 20000 20000 20000 20000 20000 20000 20000 20000 20000 20000 20000 20000
				20000 20000 20000 20000 20000 20000 20000 20000 20000 20000 20000 20000 20000 20000 20000 20000 20000 20000
				20000 20000 20000 20000 20000 20000 20000 20000 20000 20000 20000 20000 20000 20000 20000 20000 20000 20000
				20000 20000 20000 20000 20000 20000 20000 20000 20000 20000 20000 20000 20000 20000 20000 20000 20000 20000
				20000 20000 20000 20000 20000 20000 20000 20000 20000 20000 20000 20000 20000 20000 20000 20000 20000 20000
				20000 20000 20000 20000 20000 20000 20000 20000 20000 20000 20000 20000 20000 20000 20000 20000 20000 20000
				20000 20000 20000 20000 20000 20000 20000 20000 20000 20000 20000 20000 20000 20000 20000 20000 20000 20000
				20000 20000 20000 20000 20000 20000 20000 20000 20000 20000 20000 20000 20000 20000 20000 20000 20000 20000
				20000 20000 20000 20000 20000 20000 20000 20000 20000 20000 20000 20000 20000 20000 20000 20000 20000 20000
				20000 20000 20000 20000 20000 20000 20000 20000 20000 20000 20000 20000 20000 20000 20000 20000 20000 20000
				20000 20000 20000 20000 20000 20000 20000 20000 20000 20000 20000 20000 20000 20000 20000 20000 20000 20000
				20000 20000 20000 20000 20000 20000 20000 20000 20000 20000 20000 20000 20000 20000 20000 20000 20000 20000
				20000 20000 20000 20000 20000 20000 20000 20000 20000 20000 20000 20000 20000 20000 20000 20000 20000 20000
				20000 20000 20000 20000 20000 20000 20000 20000 20000 20000 20000 20000 20000 20000 20000 20000 20000 20000
				20000 20000 20000 20000 20000 20000 20000 20000 20000 20000 20000 20000 20000 20000 20000 20000 20000 20000
				20000 20000 20000 20000 20000 20000 20000 20000 20000 20000 20000 20000 20000 20000 20000 20000 20000 20000
				>;

			PS_Config_Lmt_Open_Rawdata_N = <
				0 0 0 0 0 0 0 0 0 0 0 0 0 0 0 0 0 0
				0 0 0 0 0 0 0 0 0 0 0 0 0 0 0 0 0 0
				0 0 0 0 0 0 0 0 0 0 0 0 0 0 0 0 0 0
				0 0 0 0 0 0 0 0 0 0 0 0 0 0 0 0 0 0
				0 0 0 0 0 0 0 0 0 0 0 0 0 0 0 0 0 0
				0 0 0 0 0 0 0 0 0 0 0 0 0 0 0 0 0 0
				0 0 0 0 0 0 0 0 0 0 0 0 0 0 0 0 0 0
				0 0 0 0 0 0 0 0 0 0 0 0 0 0 0 0 0 0
				0 0 0 0 0 0 0 0 0 0 0 0 0 0 0 0 0 0
				0 0 0 0 0 0 0 0 0 0 0 0 0 0 0 0 0 0
				0 0 0 0 0 0 0 0 0 0 0 0 0 0 0 0 0 0
				0 0 0 0 0 0 0 0 0 0 0 0 0 0 0 0 0 0
				0 0 0 0 0 0 0 0 0 0 0 0 0 0 0 0 0 0
				0 0 0 0 0 0 0 0 0 0 0 0 0 0 0 0 0 0
				0 0 0 0 0 0 0 0 0 0 0 0 0 0 0 0 0 0
				0 0 0 0 0 0 0 0 0 0 0 0 0 0 0 0 0 0
				0 0 0 0 0 0 0 0 0 0 0 0 0 0 0 0 0 0
				0 0 0 0 0 0 0 0 0 0 0 0 0 0 0 0 0 0
				0 0 0 0 0 0 0 0 0 0 0 0 0 0 0 0 0 0
				0 0 0 0 0 0 0 0 0 0 0 0 0 0 0 0 0 0
				0 0 0 0 0 0 0 0 0 0 0 0 0 0 0 0 0 0
				0 0 0 0 0 0 0 0 0 0 0 0 0 0 0 0 0 0
				0 0 0 0 0 0 0 0 0 0 0 0 0 0 0 0 0 0
				0 0 0 0 0 0 0 0 0 0 0 0 0 0 0 0 0 0
				0 0 0 0 0 0 0 0 0 0 0 0 0 0 0 0 0 0
				0 0 0 0 0 0 0 0 0 0 0 0 0 0 0 0 0 0
				0 0 0 0 0 0 0 0 0 0 0 0 0 0 0 0 0 0
				0 0 0 0 0 0 0 0 0 0 0 0 0 0 0 0 0 0
				0 0 0 0 0 0 0 0 0 0 0 0 0 0 0 0 0 0
				0 0 0 0 0 0 0 0 0 0 0 0 0 0 0 0 0 0
				>;

			PS_Config_Lmt_FW_Rawdata_P = <
				2000 2000 2000 2000 2000 2000 2000 2000 2000 2000 2000 2000 2000 2000 2000 2000 2000 2000
				2000 2000 2000 2000 2000 2000 2000 2000 2000 2000 2000 2000 2000 2000 2000 2000 2000 2000
				2000 2000 2000 2000 2000 2000 2000 2000 2000 2000 2000 2000 2000 2000 2000 2000 2000 2000
				2000 2000 2000 2000 2000 2000 2000 2000 2000 2000 2000 2000 2000 2000 2000 2000 2000 2000
				2000 2000 2000 2000 2000 2000 2000 2000 2000 2000 2000 2000 2000 2000 2000 2000 2000 2000
				2000 2000 2000 2000 2000 2000 2000 2000 2000 2000 2000 2000 2000 2000 2000 2000 2000 2000
				2000 2000 2000 2000 2000 2000 2000 2000 2000 2000 2000 2000 2000 2000 2000 2000 2000 2000
				2000 2000 2000 2000 2000 2000 2000 2000 2000 2000 2000 2000 2000 2000 2000 2000 2000 2000
				2000 2000 2000 2000 2000 2000 2000 2000 2000 2000 2000 2000 2000 2000 2000 2000 2000 2000
				2000 2000 2000 2000 2000 2000 2000 2000 2000 2000 2000 2000 2000 2000 2000 2000 2000 2000
				2000 2000 2000 2000 2000 2000 2000 2000 2000 2000 2000 2000 2000 2000 2000 2000 2000 2000
				2000 2000 2000 2000 2000 2000 2000 2000 2000 2000 2000 2000 2000 2000 2000 2000 2000 2000
				2000 2000 2000 2000 2000 2000 2000 2000 2000 2000 2000 2000 2000 2000 2000 2000 2000 2000
				2000 2000 2000 2000 2000 2000 2000 2000 2000 2000 2000 2000 2000 2000 2000 2000 2000 2000
				2000 2000 2000 2000 2000 2000 2000 2000 2000 2000 2000 2000 2000 2000 2000 2000 2000 2000
				2000 2000 2000 2000 2000 2000 2000 2000 2000 2000 2000 2000 2000 2000 2000 2000 2000 2000
				2000 2000 2000 2000 2000 2000 2000 2000 2000 2000 2000 2000 2000 2000 2000 2000 2000 2000
				2000 2000 2000 2000 2000 2000 2000 2000 2000 2000 2000 2000 2000 2000 2000 2000 2000 2000
				2000 2000 2000 2000 2000 2000 2000 2000 2000 2000 2000 2000 2000 2000 2000 2000 2000 2000
				2000 2000 2000 2000 2000 2000 2000 2000 2000 2000 2000 2000 2000 2000 2000 2000 2000 2000
				2000 2000 2000 2000 2000 2000 2000 2000 2000 2000 2000 2000 2000 2000 2000 2000 2000 2000
				2000 2000 2000 2000 2000 2000 2000 2000 2000 2000 2000 2000 2000 2000 2000 2000 2000 2000
				2000 2000 2000 2000 2000 2000 2000 2000 2000 2000 2000 2000 2000 2000 2000 2000 2000 2000
				2000 2000 2000 2000 2000 2000 2000 2000 2000 2000 2000 2000 2000 2000 2000 2000 2000 2000
				2000 2000 2000 2000 2000 2000 2000 2000 2000 2000 2000 2000 2000 2000 2000 2000 2000 2000
				2000 2000 2000 2000 2000 2000 2000 2000 2000 2000 2000 2000 2000 2000 2000 2000 2000 2000
				2000 2000 2000 2000 2000 2000 2000 2000 2000 2000 2000 2000 2000 2000 2000 2000 2000 2000
				2000 2000 2000 2000 2000 2000 2000 2000 2000 2000 2000 2000 2000 2000 2000 2000 2000 2000
				2000 2000 2000 2000 2000 2000 2000 2000 2000 2000 2000 2000 2000 2000 2000 2000 2000 2000
				2000 2000 2000 2000 2000 2000 2000 2000 2000 2000 2000 2000 2000 2000 2000 2000 2000 2000
				>;

			PS_Config_Lmt_FW_Rawdata_N = <
				0 0 0 0 0 0 0 0 0 0 0 0 0 0 0 0 0 0
				0 0 0 0 0 0 0 0 0 0 0 0 0 0 0 0 0 0
				0 0 0 0 0 0 0 0 0 0 0 0 0 0 0 0 0 0
				0 0 0 0 0 0 0 0 0 0 0 0 0 0 0 0 0 0
				0 0 0 0 0 0 0 0 0 0 0 0 0 0 0 0 0 0
				0 0 0 0 0 0 0 0 0 0 0 0 0 0 0 0 0 0
				0 0 0 0 0 0 0 0 0 0 0 0 0 0 0 0 0 0
				0 0 0 0 0 0 0 0 0 0 0 0 0 0 0 0 0 0
				0 0 0 0 0 0 0 0 0 0 0 0 0 0 0 0 0 0
				0 0 0 0 0 0 0 0 0 0 0 0 0 0 0 0 0 0
				0 0 0 0 0 0 0 0 0 0 0 0 0 0 0 0 0 0
				0 0 0 0 0 0 0 0 0 0 0 0 0 0 0 0 0 0
				0 0 0 0 0 0 0 0 0 0 0 0 0 0 0 0 0 0
				0 0 0 0 0 0 0 0 0 0 0 0 0 0 0 0 0 0
				0 0 0 0 0 0 0 0 0 0 0 0 0 0 0 0 0 0
				0 0 0 0 0 0 0 0 0 0 0 0 0 0 0 0 0 0
				0 0 0 0 0 0 0 0 0 0 0 0 0 0 0 0 0 0
				0 0 0 0 0 0 0 0 0 0 0 0 0 0 0 0 0 0
				0 0 0 0 0 0 0 0 0 0 0 0 0 0 0 0 0 0
				0 0 0 0 0 0 0 0 0 0 0 0 0 0 0 0 0 0
				0 0 0 0 0 0 0 0 0 0 0 0 0 0 0 0 0 0
				0 0 0 0 0 0 0 0 0 0 0 0 0 0 0 0 0 0
				0 0 0 0 0 0 0 0 0 0 0 0 0 0 0 0 0 0
				0 0 0 0 0 0 0 0 0 0 0 0 0 0 0 0 0 0
				0 0 0 0 0 0 0 0 0 0 0 0 0 0 0 0 0 0
				0 0 0 0 0 0 0 0 0 0 0 0 0 0 0 0 0 0
				0 0 0 0 0 0 0 0 0 0 0 0 0 0 0 0 0 0
				0 0 0 0 0 0 0 0 0 0 0 0 0 0 0 0 0 0
				0 0 0 0 0 0 0 0 0 0 0 0 0 0 0 0 0 0
				0 0 0 0 0 0 0 0 0 0 0 0 0 0 0 0 0 0
				>;

			PS_Config_Lmt_FW_CC_P = <
				511 511 511 511 511 511 511 511 511 511 511 511 511 511 511 511 511 511
				511 511 511 511 511 511 511 511 511 511 511 511 511 511 511 511 511 511
				511 511 511 511 511 511 511 511 511 511 511 511 511 511 511 511 511 511
				511 511 511 511 511 511 511 511 511 511 511 511 511 511 511 511 511 511
				511 511 511 511 511 511 511 511 511 511 511 511 511 511 511 511 511 511
				511 511 511 511 511 511 511 511 511 511 511 511 511 511 511 511 511 511
				511 511 511 511 511 511 511 511 511 511 511 511 511 511 511 511 511 511
				511 511 511 511 511 511 511 511 511 511 511 511 511 511 511 511 511 511
				511 511 511 511 511 511 511 511 511 511 511 511 511 511 511 511 511 511
				511 511 511 511 511 511 511 511 511 511 511 511 511 511 511 511 511 511
				511 511 511 511 511 511 511 511 511 511 511 511 511 511 511 511 511 511
				511 511 511 511 511 511 511 511 511 511 511 511 511 511 511 511 511 511
				511 511 511 511 511 511 511 511 511 511 511 511 511 511 511 511 511 511
				511 511 511 511 511 511 511 511 511 511 511 511 511 511 511 511 511 511
				511 511 511 511 511 511 511 511 511 511 511 511 511 511 511 511 511 511
				511 511 511 511 511 511 511 511 511 511 511 511 511 511 511 511 511 511
				511 511 511 511 511 511 511 511 511 511 511 511 511 511 511 511 511 511
				511 511 511 511 511 511 511 511 511 511 511 511 511 511 511 511 511 511
				511 511 511 511 511 511 511 511 511 511 511 511 511 511 511 511 511 511
				511 511 511 511 511 511 511 511 511 511 511 511 511 511 511 511 511 511
				511 511 511 511 511 511 511 511 511 511 511 511 511 511 511 511 511 511
				511 511 511 511 511 511 511 511 511 511 511 511 511 511 511 511 511 511
				511 511 511 511 511 511 511 511 511 511 511 511 511 511 511 511 511 511
				511 511 511 511 511 511 511 511 511 511 511 511 511 511 511 511 511 511
				511 511 511 511 511 511 511 511 511 511 511 511 511 511 511 511 511 511
				511 511 511 511 511 511 511 511 511 511 511 511 511 511 511 511 511 511
				511 511 511 511 511 511 511 511 511 511 511 511 511 511 511 511 511 511
				511 511 511 511 511 511 511 511 511 511 511 511 511 511 511 511 511 511
				511 511 511 511 511 511 511 511 511 511 511 511 511 511 511 511 511 511
				511 511 511 511 511 511 511 511 511 511 511 511 511 511 511 511 511 511
				>;

			PS_Config_Lmt_FW_CC_N = <
				0 0 0 0 0 0 0 0 0 0 0 0 0 0 0 0 0 0
				0 0 0 0 0 0 0 0 0 0 0 0 0 0 0 0 0 0
				0 0 0 0 0 0 0 0 0 0 0 0 0 0 0 0 0 0
				0 0 0 0 0 0 0 0 0 0 0 0 0 0 0 0 0 0
				0 0 0 0 0 0 0 0 0 0 0 0 0 0 0 0 0 0
				0 0 0 0 0 0 0 0 0 0 0 0 0 0 0 0 0 0
				0 0 0 0 0 0 0 0 0 0 0 0 0 0 0 0 0 0
				0 0 0 0 0 0 0 0 0 0 0 0 0 0 0 0 0 0
				0 0 0 0 0 0 0 0 0 0 0 0 0 0 0 0 0 0
				0 0 0 0 0 0 0 0 0 0 0 0 0 0 0 0 0 0
				0 0 0 0 0 0 0 0 0 0 0 0 0 0 0 0 0 0
				0 0 0 0 0 0 0 0 0 0 0 0 0 0 0 0 0 0
				0 0 0 0 0 0 0 0 0 0 0 0 0 0 0 0 0 0
				0 0 0 0 0 0 0 0 0 0 0 0 0 0 0 0 0 0
				0 0 0 0 0 0 0 0 0 0 0 0 0 0 0 0 0 0
				0 0 0 0 0 0 0 0 0 0 0 0 0 0 0 0 0 0
				0 0 0 0 0 0 0 0 0 0 0 0 0 0 0 0 0 0
				0 0 0 0 0 0 0 0 0 0 0 0 0 0 0 0 0 0
				0 0 0 0 0 0 0 0 0 0 0 0 0 0 0 0 0 0
				0 0 0 0 0 0 0 0 0 0 0 0 0 0 0 0 0 0
				0 0 0 0 0 0 0 0 0 0 0 0 0 0 0 0 0 0
				0 0 0 0 0 0 0 0 0 0 0 0 0 0 0 0 0 0
				0 0 0 0 0 0 0 0 0 0 0 0 0 0 0 0 0 0
				0 0 0 0 0 0 0 0 0 0 0 0 0 0 0 0 0 0
				0 0 0 0 0 0 0 0 0 0 0 0 0 0 0 0 0 0
				0 0 0 0 0 0 0 0 0 0 0 0 0 0 0 0 0 0
				0 0 0 0 0 0 0 0 0 0 0 0 0 0 0 0 0 0
				0 0 0 0 0 0 0 0 0 0 0 0 0 0 0 0 0 0
				0 0 0 0 0 0 0 0 0 0 0 0 0 0 0 0 0 0
				0 0 0 0 0 0 0 0 0 0 0 0 0 0 0 0 0 0
				>;

			PS_Config_Lmt_FW_Diff_P = <
				127 127 127 127 127 127 127 127 127 127 127 127 127 127 127 127
				127 127 127 127 127 127 127 127 127 127 127 127 127 127 127 127
				127 127 127 127 127 127 127 127 127 127 127 127 127 127 127 127
				127 127 127 127 127 127 127 127 127 127 127 127 127 127 127 127
				127 127 127 127 127 127 127 127 127 127 127 127 127 127 127 127
				127 127 127 127 127 127 127 127 127 127 127 127 127 127 127 127
				127 127 127 127 127 127 127 127 127 127 127 127 127 127 127 127
				127 127 127 127 127 127 127 127 127 127 127 127 127 127 127 127
				127 127 127 127 127 127 127 127 127 127 127 127 127 127 127 127
				127 127 127 127 127 127 127 127 127 127 127 127 127 127 127 127
				127 127 127 127 127 127 127 127 127 127 127 127 127 127 127 127
				127 127 127 127 127 127 127 127 127 127 127 127 127 127 127 127
				127 127 127 127 127 127 127 127 127 127 127 127 127 127 127 127
				127 127 127 127 127 127 127 127 127 127 127 127 127 127 127 127
				127 127 127 127 127 127 127 127 127 127 127 127 127 127 127 127
				127 127 127 127 127 127 127 127 127 127 127 127 127 127 127 127
				127 127 127 127 127 127 127 127 127 127 127 127 127 127 127 127
				127 127 127 127 127 127 127 127 127 127 127 127 127 127 127 127
				127 127 127 127 127 127 127 127 127 127 127 127 127 127 127 127
				127 127 127 127 127 127 127 127 127 127 127 127 127 127 127 127
				127 127 127 127 127 127 127 127 127 127 127 127 127 127 127 127
				127 127 127 127 127 127 127 127 127 127 127 127 127 127 127 127
				127 127 127 127 127 127 127 127 127 127 127 127 127 127 127 127
				127 127 127 127 127 127 127 127 127 127 127 127 127 127 127 127
				127 127 127 127 127 127 127 127 127 127 127 127 127 127 127 127
				127 127 127 127 127 127 127 127 127 127 127 127 127 127 127 127
				127 127 127 127 127 127 127 127 127 127 127 127 127 127 127 127
				127 127 127 127 127 127 127 127 127 127 127 127 127 127 127 127
				127 127 127 127 127 127 127 127 127 127 127 127 127 127 127 127
				127 127 127 127 127 127 127 127 127 127 127 127 127 127 127 127
				127 127 127 127 127 127 127 127 127 127 127 127 127 127 127 127
				127 127 127 127 127 127 127 127 127 127 127 127 127 127 127 127
				127 127 127 127 127 127 127 127 127 127 127 127 127 127 127 127
				127 127 127 127 127 127 127 127 127 127 127 127>;

			PS_Config_Lmt_FW_Diff_N = <
				(-127) (-127) (-127) (-127) (-127) (-127) (-127) (-127) (-127) (-127) (-127) (-127) (-127) (-127) (-127) (-127)
				(-127) (-127) (-127) (-127) (-127) (-127) (-127) (-127) (-127) (-127) (-127) (-127) (-127) (-127) (-127) (-127)
				(-127) (-127) (-127) (-127) (-127) (-127) (-127) (-127) (-127) (-127) (-127) (-127) (-127) (-127) (-127) (-127)
				(-127) (-127) (-127) (-127) (-127) (-127) (-127) (-127) (-127) (-127) (-127) (-127) (-127) (-127) (-127) (-127)
				(-127) (-127) (-127) (-127) (-127) (-127) (-127) (-127) (-127) (-127) (-127) (-127) (-127) (-127) (-127) (-127)
				(-127) (-127) (-127) (-127) (-127) (-127) (-127) (-127) (-127) (-127) (-127) (-127) (-127) (-127) (-127) (-127)
				(-127) (-127) (-127) (-127) (-127) (-127) (-127) (-127) (-127) (-127) (-127) (-127) (-127) (-127) (-127) (-127)
				(-127) (-127) (-127) (-127) (-127) (-127) (-127) (-127) (-127) (-127) (-127) (-127) (-127) (-127) (-127) (-127)
				(-127) (-127) (-127) (-127) (-127) (-127) (-127) (-127) (-127) (-127) (-127) (-127) (-127) (-127) (-127) (-127)
				(-127) (-127) (-127) (-127) (-127) (-127) (-127) (-127) (-127) (-127) (-127) (-127) (-127) (-127) (-127) (-127)
				(-127) (-127) (-127) (-127) (-127) (-127) (-127) (-127) (-127) (-127) (-127) (-127) (-127) (-127) (-127) (-127)
				(-127) (-127) (-127) (-127) (-127) (-127) (-127) (-127) (-127) (-127) (-127) (-127) (-127) (-127) (-127) (-127)
				(-127) (-127) (-127) (-127) (-127) (-127) (-127) (-127) (-127) (-127) (-127) (-127) (-127) (-127) (-127) (-127)
				(-127) (-127) (-127) (-127) (-127) (-127) (-127) (-127) (-127) (-127) (-127) (-127) (-127) (-127) (-127) (-127)
				(-127) (-127) (-127) (-127) (-127) (-127) (-127) (-127) (-127) (-127) (-127) (-127) (-127) (-127) (-127) (-127)
				(-127) (-127) (-127) (-127) (-127) (-127) (-127) (-127) (-127) (-127) (-127) (-127) (-127) (-127) (-127) (-127)
				(-127) (-127) (-127) (-127) (-127) (-127) (-127) (-127) (-127) (-127) (-127) (-127) (-127) (-127) (-127) (-127)
				(-127) (-127) (-127) (-127) (-127) (-127) (-127) (-127) (-127) (-127) (-127) (-127) (-127) (-127) (-127) (-127)
				(-127) (-127) (-127) (-127) (-127) (-127) (-127) (-127) (-127) (-127) (-127) (-127) (-127) (-127) (-127) (-127)
				(-127) (-127) (-127) (-127) (-127) (-127) (-127) (-127) (-127) (-127) (-127) (-127) (-127) (-127) (-127) (-127)
				(-127) (-127) (-127) (-127) (-127) (-127) (-127) (-127) (-127) (-127) (-127) (-127) (-127) (-127) (-127) (-127)
				(-127) (-127) (-127) (-127) (-127) (-127) (-127) (-127) (-127) (-127) (-127) (-127) (-127) (-127) (-127) (-127)
				(-127) (-127) (-127) (-127) (-127) (-127) (-127) (-127) (-127) (-127) (-127) (-127) (-127) (-127) (-127) (-127)
				(-127) (-127) (-127) (-127) (-127) (-127) (-127) (-127) (-127) (-127) (-127) (-127) (-127) (-127) (-127) (-127)
				(-127) (-127) (-127) (-127) (-127) (-127) (-127) (-127) (-127) (-127) (-127) (-127) (-127) (-127) (-127) (-127)
				(-127) (-127) (-127) (-127) (-127) (-127) (-127) (-127) (-127) (-127) (-127) (-127) (-127) (-127) (-127) (-127)
				(-127) (-127) (-127) (-127) (-127) (-127) (-127) (-127) (-127) (-127) (-127) (-127) (-127) (-127) (-127) (-127)
				(-127) (-127) (-127) (-127) (-127) (-127) (-127) (-127) (-127) (-127) (-127) (-127) (-127) (-127) (-127) (-127)
				(-127) (-127) (-127) (-127) (-127) (-127) (-127) (-127) (-127) (-127) (-127) (-127) (-127) (-127) (-127) (-127)
				(-127) (-127) (-127) (-127) (-127) (-127) (-127) (-127) (-127) (-127) (-127) (-127) (-127) (-127) (-127) (-127)
				(-127) (-127) (-127) (-127) (-127) (-127) (-127) (-127) (-127) (-127) (-127) (-127) (-127) (-127) (-127) (-127)
				(-127) (-127) (-127) (-127) (-127) (-127) (-127) (-127) (-127) (-127) (-127) (-127) (-127) (-127) (-127) (-127)
				(-127) (-127) (-127) (-127) (-127) (-127) (-127) (-127) (-127) (-127) (-127) (-127) (-127) (-127) (-127) (-127)
				(-127) (-127) (-127) (-127) (-127) (-127) (-127) (-127) (-127) (-127) (-127) (-127)>;

			PS_Config_Diff_Test_Frame = <50>;
		};

		/* SM23 currently */
		novatek-mp-criteria-1114@0 {
			#address-cells = <1>;
			#size-cells = <0>;
			compatible = "novatek-mp-criteria-1114";

			/* MP Config */
			IC_X_CFG_SIZE = <18>;
			IC_Y_CFG_SIZE = <34>;
			IC_KEY_CFG_SIZE = <4>;
			X_Channel = <18>;
			Y_Channel = <34>;
			AIN_X = <0 1 2 3 4 5 6 7 8 9 10 11 12 13 14 15 16 17>;
			AIN_Y = <0 1 2 3 4 5 6 7 8 9 10 11 12 13 14 15
					16 17 18 19 20 21 22 23 24 25 26 27 28 29 30
					31 32 33>;
			AIN_KEY = <0 1 2 0xFF>;

			/* MP Criteria */
			PS_Config_Lmt_Short_Rawdata_P = <
				20000 20000 20000 20000 20000 20000 20000 20000 20000 20000 20000 20000 20000 20000 20000 20000 20000 20000
				20000 20000 20000 20000 20000 20000 20000 20000 20000 20000 20000 20000 20000 20000 20000 20000 20000 20000
				20000 20000 20000 20000 20000 20000 20000 20000 20000 20000 20000 20000 20000 20000 20000 20000 20000 20000
				20000 20000 20000 20000 20000 20000 20000 20000 20000 20000 20000 20000 20000 20000 20000 20000 20000 20000
				20000 20000 20000 20000 20000 20000 20000 20000 20000 20000 20000 20000 20000 20000 20000 20000 20000 20000
				20000 20000 20000 20000 20000 20000 20000 20000 20000 20000 20000 20000 20000 20000 20000 20000 20000 20000
				20000 20000 20000 20000 20000 20000 20000 20000 20000 20000 20000 20000 20000 20000 20000 20000 20000 20000
				20000 20000 20000 20000 20000 20000 20000 20000 20000 20000 20000 20000 20000 20000 20000 20000 20000 20000
				20000 20000 20000 20000 20000 20000 20000 20000 20000 20000 20000 20000 20000 20000 20000 20000 20000 20000
				20000 20000 20000 20000 20000 20000 20000 20000 20000 20000 20000 20000 20000 20000 20000 20000 20000 20000
				20000 20000 20000 20000 20000 20000 20000 20000 20000 20000 20000 20000 20000 20000 20000 20000 20000 20000
				20000 20000 20000 20000 20000 20000 20000 20000 20000 20000 20000 20000 20000 20000 20000 20000 20000 20000
				20000 20000 20000 20000 20000 20000 20000 20000 20000 20000 20000 20000 20000 20000 20000 20000 20000 20000
				20000 20000 20000 20000 20000 20000 20000 20000 20000 20000 20000 20000 20000 20000 20000 20000 20000 20000
				20000 20000 20000 20000 20000 20000 20000 20000 20000 20000 20000 20000 20000 20000 20000 20000 20000 20000
				20000 20000 20000 20000 20000 20000 20000 20000 20000 20000 20000 20000 20000 20000 20000 20000 20000 20000
				20000 20000 20000 20000 20000 20000 20000 20000 20000 20000 20000 20000 20000 20000 20000 20000 20000 20000
				20000 20000 20000 20000 20000 20000 20000 20000 20000 20000 20000 20000 20000 20000 20000 20000 20000 20000
				20000 20000 20000 20000 20000 20000 20000 20000 20000 20000 20000 20000 20000 20000 20000 20000 20000 20000
				20000 20000 20000 20000 20000 20000 20000 20000 20000 20000 20000 20000 20000 20000 20000 20000 20000 20000
				20000 20000 20000 20000 20000 20000 20000 20000 20000 20000 20000 20000 20000 20000 20000 20000 20000 20000
				20000 20000 20000 20000 20000 20000 20000 20000 20000 20000 20000 20000 20000 20000 20000 20000 20000 20000
				20000 20000 20000 20000 20000 20000 20000 20000 20000 20000 20000 20000 20000 20000 20000 20000 20000 20000
				20000 20000 20000 20000 20000 20000 20000 20000 20000 20000 20000 20000 20000 20000 20000 20000 20000 20000
				20000 20000 20000 20000 20000 20000 20000 20000 20000 20000 20000 20000 20000 20000 20000 20000 20000 20000
				20000 20000 20000 20000 20000 20000 20000 20000 20000 20000 20000 20000 20000 20000 20000 20000 20000 20000
				20000 20000 20000 20000 20000 20000 20000 20000 20000 20000 20000 20000 20000 20000 20000 20000 20000 20000
				20000 20000 20000 20000 20000 20000 20000 20000 20000 20000 20000 20000 20000 20000 20000 20000 20000 20000
				20000 20000 20000 20000 20000 20000 20000 20000 20000 20000 20000 20000 20000 20000 20000 20000 20000 20000
				20000 20000 20000 20000 20000 20000 20000 20000 20000 20000 20000 20000 20000 20000 20000 20000 20000 20000
				20000 20000 20000 20000 20000 20000 20000 20000 20000 20000 20000 20000 20000 20000 20000 20000 20000 20000
				20000 20000 20000 20000 20000 20000 20000 20000 20000 20000 20000 20000 20000 20000 20000 20000 20000 20000
				20000 20000 20000 20000 20000 20000 20000 20000 20000 20000 20000 20000 20000 20000 20000 20000 20000 20000
				20000 20000 20000 20000 20000 20000 20000 20000 20000 20000 20000 20000 20000 20000 20000 20000 20000 20000
				>;

			PS_Config_Lmt_Short_Rawdata_N = <
				0 0 0 0 0 0 0 0 0 0 0 0 0 0 0 0 0 0
				0 0 0 0 0 0 0 0 0 0 0 0 0 0 0 0 0 0
				0 0 0 0 0 0 0 0 0 0 0 0 0 0 0 0 0 0
				0 0 0 0 0 0 0 0 0 0 0 0 0 0 0 0 0 0
				0 0 0 0 0 0 0 0 0 0 0 0 0 0 0 0 0 0
				0 0 0 0 0 0 0 0 0 0 0 0 0 0 0 0 0 0
				0 0 0 0 0 0 0 0 0 0 0 0 0 0 0 0 0 0
				0 0 0 0 0 0 0 0 0 0 0 0 0 0 0 0 0 0
				0 0 0 0 0 0 0 0 0 0 0 0 0 0 0 0 0 0
				0 0 0 0 0 0 0 0 0 0 0 0 0 0 0 0 0 0
				0 0 0 0 0 0 0 0 0 0 0 0 0 0 0 0 0 0
				0 0 0 0 0 0 0 0 0 0 0 0 0 0 0 0 0 0
				0 0 0 0 0 0 0 0 0 0 0 0 0 0 0 0 0 0
				0 0 0 0 0 0 0 0 0 0 0 0 0 0 0 0 0 0
				0 0 0 0 0 0 0 0 0 0 0 0 0 0 0 0 0 0
				0 0 0 0 0 0 0 0 0 0 0 0 0 0 0 0 0 0
				0 0 0 0 0 0 0 0 0 0 0 0 0 0 0 0 0 0
				0 0 0 0 0 0 0 0 0 0 0 0 0 0 0 0 0 0
				0 0 0 0 0 0 0 0 0 0 0 0 0 0 0 0 0 0
				0 0 0 0 0 0 0 0 0 0 0 0 0 0 0 0 0 0
				0 0 0 0 0 0 0 0 0 0 0 0 0 0 0 0 0 0
				0 0 0 0 0 0 0 0 0 0 0 0 0 0 0 0 0 0
				0 0 0 0 0 0 0 0 0 0 0 0 0 0 0 0 0 0
				0 0 0 0 0 0 0 0 0 0 0 0 0 0 0 0 0 0
				0 0 0 0 0 0 0 0 0 0 0 0 0 0 0 0 0 0
				0 0 0 0 0 0 0 0 0 0 0 0 0 0 0 0 0 0
				0 0 0 0 0 0 0 0 0 0 0 0 0 0 0 0 0 0
				0 0 0 0 0 0 0 0 0 0 0 0 0 0 0 0 0 0
				0 0 0 0 0 0 0 0 0 0 0 0 0 0 0 0 0 0
				0 0 0 0 0 0 0 0 0 0 0 0 0 0 0 0 0 0
				0 0 0 0 0 0 0 0 0 0 0 0 0 0 0 0 0 0
				0 0 0 0 0 0 0 0 0 0 0 0 0 0 0 0 0 0
				0 0 0 0 0 0 0 0 0 0 0 0 0 0 0 0 0 0
				0 0 0 0 0 0 0 0 0 0 0 0 0 0 0 0 0 0
				>;

			PS_Config_Lmt_Open_Rawdata_P = <
				20000 20000 20000 20000 20000 20000 20000 20000 20000 20000 20000 20000 20000 20000 20000 20000 20000 20000
				20000 20000 20000 20000 20000 20000 20000 20000 20000 20000 20000 20000 20000 20000 20000 20000 20000 20000
				20000 20000 20000 20000 20000 20000 20000 20000 20000 20000 20000 20000 20000 20000 20000 20000 20000 20000
				20000 20000 20000 20000 20000 20000 20000 20000 20000 20000 20000 20000 20000 20000 20000 20000 20000 20000
				20000 20000 20000 20000 20000 20000 20000 20000 20000 20000 20000 20000 20000 20000 20000 20000 20000 20000
				20000 20000 20000 20000 20000 20000 20000 20000 20000 20000 20000 20000 20000 20000 20000 20000 20000 20000
				20000 20000 20000 20000 20000 20000 20000 20000 20000 20000 20000 20000 20000 20000 20000 20000 20000 20000
				20000 20000 20000 20000 20000 20000 20000 20000 20000 20000 20000 20000 20000 20000 20000 20000 20000 20000
				20000 20000 20000 20000 20000 20000 20000 20000 20000 20000 20000 20000 20000 20000 20000 20000 20000 20000
				20000 20000 20000 20000 20000 20000 20000 20000 20000 20000 20000 20000 20000 20000 20000 20000 20000 20000
				20000 20000 20000 20000 20000 20000 20000 20000 20000 20000 20000 20000 20000 20000 20000 20000 20000 20000
				20000 20000 20000 20000 20000 20000 20000 20000 20000 20000 20000 20000 20000 20000 20000 20000 20000 20000
				20000 20000 20000 20000 20000 20000 20000 20000 20000 20000 20000 20000 20000 20000 20000 20000 20000 20000
				20000 20000 20000 20000 20000 20000 20000 20000 20000 20000 20000 20000 20000 20000 20000 20000 20000 20000
				20000 20000 20000 20000 20000 20000 20000 20000 20000 20000 20000 20000 20000 20000 20000 20000 20000 20000
				20000 20000 20000 20000 20000 20000 20000 20000 20000 20000 20000 20000 20000 20000 20000 20000 20000 20000
				20000 20000 20000 20000 20000 20000 20000 20000 20000 20000 20000 20000 20000 20000 20000 20000 20000 20000
				20000 20000 20000 20000 20000 20000 20000 20000 20000 20000 20000 20000 20000 20000 20000 20000 20000 20000
				20000 20000 20000 20000 20000 20000 20000 20000 20000 20000 20000 20000 20000 20000 20000 20000 20000 20000
				20000 20000 20000 20000 20000 20000 20000 20000 20000 20000 20000 20000 20000 20000 20000 20000 20000 20000
				20000 20000 20000 20000 20000 20000 20000 20000 20000 20000 20000 20000 20000 20000 20000 20000 20000 20000
				20000 20000 20000 20000 20000 20000 20000 20000 20000 20000 20000 20000 20000 20000 20000 20000 20000 20000
				20000 20000 20000 20000 20000 20000 20000 20000 20000 20000 20000 20000 20000 20000 20000 20000 20000 20000
				20000 20000 20000 20000 20000 20000 20000 20000 20000 20000 20000 20000 20000 20000 20000 20000 20000 20000
				20000 20000 20000 20000 20000 20000 20000 20000 20000 20000 20000 20000 20000 20000 20000 20000 20000 20000
				20000 20000 20000 20000 20000 20000 20000 20000 20000 20000 20000 20000 20000 20000 20000 20000 20000 20000
				20000 20000 20000 20000 20000 20000 20000 20000 20000 20000 20000 20000 20000 20000 20000 20000 20000 20000
				20000 20000 20000 20000 20000 20000 20000 20000 20000 20000 20000 20000 20000 20000 20000 20000 20000 20000
				20000 20000 20000 20000 20000 20000 20000 20000 20000 20000 20000 20000 20000 20000 20000 20000 20000 20000
				20000 20000 20000 20000 20000 20000 20000 20000 20000 20000 20000 20000 20000 20000 20000 20000 20000 20000
				20000 20000 20000 20000 20000 20000 20000 20000 20000 20000 20000 20000 20000 20000 20000 20000 20000 20000
				20000 20000 20000 20000 20000 20000 20000 20000 20000 20000 20000 20000 20000 20000 20000 20000 20000 20000
				20000 20000 20000 20000 20000 20000 20000 20000 20000 20000 20000 20000 20000 20000 20000 20000 20000 20000
				20000 20000 20000 20000 20000 20000 20000 20000 20000 20000 20000 20000 20000 20000 20000 20000 20000 20000
				>;

			PS_Config_Lmt_Open_Rawdata_N = <
				0 0 0 0 0 0 0 0 0 0 0 0 0 0 0 0 0 0
				0 0 0 0 0 0 0 0 0 0 0 0 0 0 0 0 0 0
				0 0 0 0 0 0 0 0 0 0 0 0 0 0 0 0 0 0
				0 0 0 0 0 0 0 0 0 0 0 0 0 0 0 0 0 0
				0 0 0 0 0 0 0 0 0 0 0 0 0 0 0 0 0 0
				0 0 0 0 0 0 0 0 0 0 0 0 0 0 0 0 0 0
				0 0 0 0 0 0 0 0 0 0 0 0 0 0 0 0 0 0
				0 0 0 0 0 0 0 0 0 0 0 0 0 0 0 0 0 0
				0 0 0 0 0 0 0 0 0 0 0 0 0 0 0 0 0 0
				0 0 0 0 0 0 0 0 0 0 0 0 0 0 0 0 0 0
				0 0 0 0 0 0 0 0 0 0 0 0 0 0 0 0 0 0
				0 0 0 0 0 0 0 0 0 0 0 0 0 0 0 0 0 0
				0 0 0 0 0 0 0 0 0 0 0 0 0 0 0 0 0 0
				0 0 0 0 0 0 0 0 0 0 0 0 0 0 0 0 0 0
				0 0 0 0 0 0 0 0 0 0 0 0 0 0 0 0 0 0
				0 0 0 0 0 0 0 0 0 0 0 0 0 0 0 0 0 0
				0 0 0 0 0 0 0 0 0 0 0 0 0 0 0 0 0 0
				0 0 0 0 0 0 0 0 0 0 0 0 0 0 0 0 0 0
				0 0 0 0 0 0 0 0 0 0 0 0 0 0 0 0 0 0
				0 0 0 0 0 0 0 0 0 0 0 0 0 0 0 0 0 0
				0 0 0 0 0 0 0 0 0 0 0 0 0 0 0 0 0 0
				0 0 0 0 0 0 0 0 0 0 0 0 0 0 0 0 0 0
				0 0 0 0 0 0 0 0 0 0 0 0 0 0 0 0 0 0
				0 0 0 0 0 0 0 0 0 0 0 0 0 0 0 0 0 0
				0 0 0 0 0 0 0 0 0 0 0 0 0 0 0 0 0 0
				0 0 0 0 0 0 0 0 0 0 0 0 0 0 0 0 0 0
				0 0 0 0 0 0 0 0 0 0 0 0 0 0 0 0 0 0
				0 0 0 0 0 0 0 0 0 0 0 0 0 0 0 0 0 0
				0 0 0 0 0 0 0 0 0 0 0 0 0 0 0 0 0 0
				0 0 0 0 0 0 0 0 0 0 0 0 0 0 0 0 0 0
				0 0 0 0 0 0 0 0 0 0 0 0 0 0 0 0 0 0
				0 0 0 0 0 0 0 0 0 0 0 0 0 0 0 0 0 0
				0 0 0 0 0 0 0 0 0 0 0 0 0 0 0 0 0 0
				0 0 0 0 0 0 0 0 0 0 0 0 0 0 0 0 0 0
				>;

			PS_Config_Lmt_FW_Rawdata_P = <
				2000 2000 2000 2000 2000 2000 2000 2000 2000 2000 2000 2000 2000 2000 2000 2000 2000 2000
				2000 2000 2000 2000 2000 2000 2000 2000 2000 2000 2000 2000 2000 2000 2000 2000 2000 2000
				2000 2000 2000 2000 2000 2000 2000 2000 2000 2000 2000 2000 2000 2000 2000 2000 2000 2000
				2000 2000 2000 2000 2000 2000 2000 2000 2000 2000 2000 2000 2000 2000 2000 2000 2000 2000
				2000 2000 2000 2000 2000 2000 2000 2000 2000 2000 2000 2000 2000 2000 2000 2000 2000 2000
				2000 2000 2000 2000 2000 2000 2000 2000 2000 2000 2000 2000 2000 2000 2000 2000 2000 2000
				2000 2000 2000 2000 2000 2000 2000 2000 2000 2000 2000 2000 2000 2000 2000 2000 2000 2000
				2000 2000 2000 2000 2000 2000 2000 2000 2000 2000 2000 2000 2000 2000 2000 2000 2000 2000
				2000 2000 2000 2000 2000 2000 2000 2000 2000 2000 2000 2000 2000 2000 2000 2000 2000 2000
				2000 2000 2000 2000 2000 2000 2000 2000 2000 2000 2000 2000 2000 2000 2000 2000 2000 2000
				2000 2000 2000 2000 2000 2000 2000 2000 2000 2000 2000 2000 2000 2000 2000 2000 2000 2000
				2000 2000 2000 2000 2000 2000 2000 2000 2000 2000 2000 2000 2000 2000 2000 2000 2000 2000
				2000 2000 2000 2000 2000 2000 2000 2000 2000 2000 2000 2000 2000 2000 2000 2000 2000 2000
				2000 2000 2000 2000 2000 2000 2000 2000 2000 2000 2000 2000 2000 2000 2000 2000 2000 2000
				2000 2000 2000 2000 2000 2000 2000 2000 2000 2000 2000 2000 2000 2000 2000 2000 2000 2000
				2000 2000 2000 2000 2000 2000 2000 2000 2000 2000 2000 2000 2000 2000 2000 2000 2000 2000
				2000 2000 2000 2000 2000 2000 2000 2000 2000 2000 2000 2000 2000 2000 2000 2000 2000 2000
				2000 2000 2000 2000 2000 2000 2000 2000 2000 2000 2000 2000 2000 2000 2000 2000 2000 2000
				2000 2000 2000 2000 2000 2000 2000 2000 2000 2000 2000 2000 2000 2000 2000 2000 2000 2000
				2000 2000 2000 2000 2000 2000 2000 2000 2000 2000 2000 2000 2000 2000 2000 2000 2000 2000
				2000 2000 2000 2000 2000 2000 2000 2000 2000 2000 2000 2000 2000 2000 2000 2000 2000 2000
				2000 2000 2000 2000 2000 2000 2000 2000 2000 2000 2000 2000 2000 2000 2000 2000 2000 2000
				2000 2000 2000 2000 2000 2000 2000 2000 2000 2000 2000 2000 2000 2000 2000 2000 2000 2000
				2000 2000 2000 2000 2000 2000 2000 2000 2000 2000 2000 2000 2000 2000 2000 2000 2000 2000
				2000 2000 2000 2000 2000 2000 2000 2000 2000 2000 2000 2000 2000 2000 2000 2000 2000 2000
				2000 2000 2000 2000 2000 2000 2000 2000 2000 2000 2000 2000 2000 2000 2000 2000 2000 2000
				2000 2000 2000 2000 2000 2000 2000 2000 2000 2000 2000 2000 2000 2000 2000 2000 2000 2000
				2000 2000 2000 2000 2000 2000 2000 2000 2000 2000 2000 2000 2000 2000 2000 2000 2000 2000
				2000 2000 2000 2000 2000 2000 2000 2000 2000 2000 2000 2000 2000 2000 2000 2000 2000 2000
				2000 2000 2000 2000 2000 2000 2000 2000 2000 2000 2000 2000 2000 2000 2000 2000 2000 2000
				2000 2000 2000 2000 2000 2000 2000 2000 2000 2000 2000 2000 2000 2000 2000 2000 2000 2000
				2000 2000 2000 2000 2000 2000 2000 2000 2000 2000 2000 2000 2000 2000 2000 2000 2000 2000
				2000 2000 2000 2000 2000 2000 2000 2000 2000 2000 2000 2000 2000 2000 2000 2000 2000 2000
				2000 2000 2000 2000 2000 2000 2000 2000 2000 2000 2000 2000 2000 2000 2000 2000 2000 2000
				>;

			PS_Config_Lmt_FW_Rawdata_N = <
				0 0 0 0 0 0 0 0 0 0 0 0 0 0 0 0 0 0
				0 0 0 0 0 0 0 0 0 0 0 0 0 0 0 0 0 0
				0 0 0 0 0 0 0 0 0 0 0 0 0 0 0 0 0 0
				0 0 0 0 0 0 0 0 0 0 0 0 0 0 0 0 0 0
				0 0 0 0 0 0 0 0 0 0 0 0 0 0 0 0 0 0
				0 0 0 0 0 0 0 0 0 0 0 0 0 0 0 0 0 0
				0 0 0 0 0 0 0 0 0 0 0 0 0 0 0 0 0 0
				0 0 0 0 0 0 0 0 0 0 0 0 0 0 0 0 0 0
				0 0 0 0 0 0 0 0 0 0 0 0 0 0 0 0 0 0
				0 0 0 0 0 0 0 0 0 0 0 0 0 0 0 0 0 0
				0 0 0 0 0 0 0 0 0 0 0 0 0 0 0 0 0 0
				0 0 0 0 0 0 0 0 0 0 0 0 0 0 0 0 0 0
				0 0 0 0 0 0 0 0 0 0 0 0 0 0 0 0 0 0
				0 0 0 0 0 0 0 0 0 0 0 0 0 0 0 0 0 0
				0 0 0 0 0 0 0 0 0 0 0 0 0 0 0 0 0 0
				0 0 0 0 0 0 0 0 0 0 0 0 0 0 0 0 0 0
				0 0 0 0 0 0 0 0 0 0 0 0 0 0 0 0 0 0
				0 0 0 0 0 0 0 0 0 0 0 0 0 0 0 0 0 0
				0 0 0 0 0 0 0 0 0 0 0 0 0 0 0 0 0 0
				0 0 0 0 0 0 0 0 0 0 0 0 0 0 0 0 0 0
				0 0 0 0 0 0 0 0 0 0 0 0 0 0 0 0 0 0
				0 0 0 0 0 0 0 0 0 0 0 0 0 0 0 0 0 0
				0 0 0 0 0 0 0 0 0 0 0 0 0 0 0 0 0 0
				0 0 0 0 0 0 0 0 0 0 0 0 0 0 0 0 0 0
				0 0 0 0 0 0 0 0 0 0 0 0 0 0 0 0 0 0
				0 0 0 0 0 0 0 0 0 0 0 0 0 0 0 0 0 0
				0 0 0 0 0 0 0 0 0 0 0 0 0 0 0 0 0 0
				0 0 0 0 0 0 0 0 0 0 0 0 0 0 0 0 0 0
				0 0 0 0 0 0 0 0 0 0 0 0 0 0 0 0 0 0
				0 0 0 0 0 0 0 0 0 0 0 0 0 0 0 0 0 0
				0 0 0 0 0 0 0 0 0 0 0 0 0 0 0 0 0 0
				0 0 0 0 0 0 0 0 0 0 0 0 0 0 0 0 0 0
				0 0 0 0 0 0 0 0 0 0 0 0 0 0 0 0 0 0
				0 0 0 0 0 0 0 0 0 0 0 0 0 0 0 0 0 0
				>;

			PS_Config_Lmt_FW_CC_P = <
				511 511 511 511 511 511 511 511 511 511 511 511 511 511 511 511 511 511
				511 511 511 511 511 511 511 511 511 511 511 511 511 511 511 511 511 511
				511 511 511 511 511 511 511 511 511 511 511 511 511 511 511 511 511 511
				511 511 511 511 511 511 511 511 511 511 511 511 511 511 511 511 511 511
				511 511 511 511 511 511 511 511 511 511 511 511 511 511 511 511 511 511
				511 511 511 511 511 511 511 511 511 511 511 511 511 511 511 511 511 511
				511 511 511 511 511 511 511 511 511 511 511 511 511 511 511 511 511 511
				511 511 511 511 511 511 511 511 511 511 511 511 511 511 511 511 511 511
				511 511 511 511 511 511 511 511 511 511 511 511 511 511 511 511 511 511
				511 511 511 511 511 511 511 511 511 511 511 511 511 511 511 511 511 511
				511 511 511 511 511 511 511 511 511 511 511 511 511 511 511 511 511 511
				511 511 511 511 511 511 511 511 511 511 511 511 511 511 511 511 511 511
				511 511 511 511 511 511 511 511 511 511 511 511 511 511 511 511 511 511
				511 511 511 511 511 511 511 511 511 511 511 511 511 511 511 511 511 511
				511 511 511 511 511 511 511 511 511 511 511 511 511 511 511 511 511 511
				511 511 511 511 511 511 511 511 511 511 511 511 511 511 511 511 511 511
				511 511 511 511 511 511 511 511 511 511 511 511 511 511 511 511 511 511
				511 511 511 511 511 511 511 511 511 511 511 511 511 511 511 511 511 511
				511 511 511 511 511 511 511 511 511 511 511 511 511 511 511 511 511 511
				511 511 511 511 511 511 511 511 511 511 511 511 511 511 511 511 511 511
				511 511 511 511 511 511 511 511 511 511 511 511 511 511 511 511 511 511
				511 511 511 511 511 511 511 511 511 511 511 511 511 511 511 511 511 511
				511 511 511 511 511 511 511 511 511 511 511 511 511 511 511 511 511 511
				511 511 511 511 511 511 511 511 511 511 511 511 511 511 511 511 511 511
				511 511 511 511 511 511 511 511 511 511 511 511 511 511 511 511 511 511
				511 511 511 511 511 511 511 511 511 511 511 511 511 511 511 511 511 511
				511 511 511 511 511 511 511 511 511 511 511 511 511 511 511 511 511 511
				511 511 511 511 511 511 511 511 511 511 511 511 511 511 511 511 511 511
				511 511 511 511 511 511 511 511 511 511 511 511 511 511 511 511 511 511
				511 511 511 511 511 511 511 511 511 511 511 511 511 511 511 511 511 511
				511 511 511 511 511 511 511 511 511 511 511 511 511 511 511 511 511 511
				511 511 511 511 511 511 511 511 511 511 511 511 511 511 511 511 511 511
				511 511 511 511 511 511 511 511 511 511 511 511 511 511 511 511 511 511
				511 511 511 511 511 511 511 511 511 511 511 511 511 511 511 511 511 511
				>;

			PS_Config_Lmt_FW_CC_N = <
				0 0 0 0 0 0 0 0 0 0 0 0 0 0 0 0 0 0
				0 0 0 0 0 0 0 0 0 0 0 0 0 0 0 0 0 0
				0 0 0 0 0 0 0 0 0 0 0 0 0 0 0 0 0 0
				0 0 0 0 0 0 0 0 0 0 0 0 0 0 0 0 0 0
				0 0 0 0 0 0 0 0 0 0 0 0 0 0 0 0 0 0
				0 0 0 0 0 0 0 0 0 0 0 0 0 0 0 0 0 0
				0 0 0 0 0 0 0 0 0 0 0 0 0 0 0 0 0 0
				0 0 0 0 0 0 0 0 0 0 0 0 0 0 0 0 0 0
				0 0 0 0 0 0 0 0 0 0 0 0 0 0 0 0 0 0
				0 0 0 0 0 0 0 0 0 0 0 0 0 0 0 0 0 0
				0 0 0 0 0 0 0 0 0 0 0 0 0 0 0 0 0 0
				0 0 0 0 0 0 0 0 0 0 0 0 0 0 0 0 0 0
				0 0 0 0 0 0 0 0 0 0 0 0 0 0 0 0 0 0
				0 0 0 0 0 0 0 0 0 0 0 0 0 0 0 0 0 0
				0 0 0 0 0 0 0 0 0 0 0 0 0 0 0 0 0 0
				0 0 0 0 0 0 0 0 0 0 0 0 0 0 0 0 0 0
				0 0 0 0 0 0 0 0 0 0 0 0 0 0 0 0 0 0
				0 0 0 0 0 0 0 0 0 0 0 0 0 0 0 0 0 0
				0 0 0 0 0 0 0 0 0 0 0 0 0 0 0 0 0 0
				0 0 0 0 0 0 0 0 0 0 0 0 0 0 0 0 0 0
				0 0 0 0 0 0 0 0 0 0 0 0 0 0 0 0 0 0
				0 0 0 0 0 0 0 0 0 0 0 0 0 0 0 0 0 0
				0 0 0 0 0 0 0 0 0 0 0 0 0 0 0 0 0 0
				0 0 0 0 0 0 0 0 0 0 0 0 0 0 0 0 0 0
				0 0 0 0 0 0 0 0 0 0 0 0 0 0 0 0 0 0
				0 0 0 0 0 0 0 0 0 0 0 0 0 0 0 0 0 0
				0 0 0 0 0 0 0 0 0 0 0 0 0 0 0 0 0 0
				0 0 0 0 0 0 0 0 0 0 0 0 0 0 0 0 0 0
				0 0 0 0 0 0 0 0 0 0 0 0 0 0 0 0 0 0
				0 0 0 0 0 0 0 0 0 0 0 0 0 0 0 0 0 0
				0 0 0 0 0 0 0 0 0 0 0 0 0 0 0 0 0 0
				0 0 0 0 0 0 0 0 0 0 0 0 0 0 0 0 0 0
				0 0 0 0 0 0 0 0 0 0 0 0 0 0 0 0 0 0
				0 0 0 0 0 0 0 0 0 0 0 0 0 0 0 0 0 0
				>;

			PS_Config_Lmt_FW_Diff_P = <
				127 127 127 127 127 127 127 127 127 127 127 127 127 127 127 127
				127 127 127 127 127 127 127 127 127 127 127 127 127 127 127 127
				127 127 127 127 127 127 127 127 127 127 127 127 127 127 127 127
				127 127 127 127 127 127 127 127 127 127 127 127 127 127 127 127
				127 127 127 127 127 127 127 127 127 127 127 127 127 127 127 127
				127 127 127 127 127 127 127 127 127 127 127 127 127 127 127 127
				127 127 127 127 127 127 127 127 127 127 127 127 127 127 127 127
				127 127 127 127 127 127 127 127 127 127 127 127 127 127 127 127
				127 127 127 127 127 127 127 127 127 127 127 127 127 127 127 127
				127 127 127 127 127 127 127 127 127 127 127 127 127 127 127 127
				127 127 127 127 127 127 127 127 127 127 127 127 127 127 127 127
				127 127 127 127 127 127 127 127 127 127 127 127 127 127 127 127
				127 127 127 127 127 127 127 127 127 127 127 127 127 127 127 127
				127 127 127 127 127 127 127 127 127 127 127 127 127 127 127 127
				127 127 127 127 127 127 127 127 127 127 127 127 127 127 127 127
				127 127 127 127 127 127 127 127 127 127 127 127 127 127 127 127
				127 127 127 127 127 127 127 127 127 127 127 127 127 127 127 127
				127 127 127 127 127 127 127 127 127 127 127 127 127 127 127 127
				127 127 127 127 127 127 127 127 127 127 127 127 127 127 127 127
				127 127 127 127 127 127 127 127 127 127 127 127 127 127 127 127
				127 127 127 127 127 127 127 127 127 127 127 127 127 127 127 127
				127 127 127 127 127 127 127 127 127 127 127 127 127 127 127 127
				127 127 127 127 127 127 127 127 127 127 127 127 127 127 127 127
				127 127 127 127 127 127 127 127 127 127 127 127 127 127 127 127
				127 127 127 127 127 127 127 127 127 127 127 127 127 127 127 127
				127 127 127 127 127 127 127 127 127 127 127 127 127 127 127 127
				127 127 127 127 127 127 127 127 127 127 127 127 127 127 127 127
				127 127 127 127 127 127 127 127 127 127 127 127 127 127 127 127
				127 127 127 127 127 127 127 127 127 127 127 127 127 127 127 127
				127 127 127 127 127 127 127 127 127 127 127 127 127 127 127 127
				127 127 127 127 127 127 127 127 127 127 127 127 127 127 127 127
				127 127 127 127 127 127 127 127 127 127 127 127 127 127 127 127
				127 127 127 127 127 127 127 127 127 127 127 127 127 127 127 127
				127 127 127 127 127 127 127 127 127 127 127 127 127 127 127 127
				127 127 127 127 127 127 127 127 127 127 127 127 127 127 127 127
				127 127 127 127 127 127 127 127 127 127 127 127 127 127 127 127
				127 127 127 127 127 127 127 127 127 127 127 127 127 127 127 127
				127 127 127 127 127 127 127 127 127 127 127 127 127 127 127 127
				127 127 127 127>;

			PS_Config_Lmt_FW_Diff_N = <
				(-127) (-127) (-127) (-127) (-127) (-127) (-127) (-127) (-127) (-127) (-127) (-127) (-127) (-127) (-127) (-127)
				(-127) (-127) (-127) (-127) (-127) (-127) (-127) (-127) (-127) (-127) (-127) (-127) (-127) (-127) (-127) (-127)
				(-127) (-127) (-127) (-127) (-127) (-127) (-127) (-127) (-127) (-127) (-127) (-127) (-127) (-127) (-127) (-127)
				(-127) (-127) (-127) (-127) (-127) (-127) (-127) (-127) (-127) (-127) (-127) (-127) (-127) (-127) (-127) (-127)
				(-127) (-127) (-127) (-127) (-127) (-127) (-127) (-127) (-127) (-127) (-127) (-127) (-127) (-127) (-127) (-127)
				(-127) (-127) (-127) (-127) (-127) (-127) (-127) (-127) (-127) (-127) (-127) (-127) (-127) (-127) (-127) (-127)
				(-127) (-127) (-127) (-127) (-127) (-127) (-127) (-127) (-127) (-127) (-127) (-127) (-127) (-127) (-127) (-127)
				(-127) (-127) (-127) (-127) (-127) (-127) (-127) (-127) (-127) (-127) (-127) (-127) (-127) (-127) (-127) (-127)
				(-127) (-127) (-127) (-127) (-127) (-127) (-127) (-127) (-127) (-127) (-127) (-127) (-127) (-127) (-127) (-127)
				(-127) (-127) (-127) (-127) (-127) (-127) (-127) (-127) (-127) (-127) (-127) (-127) (-127) (-127) (-127) (-127)
				(-127) (-127) (-127) (-127) (-127) (-127) (-127) (-127) (-127) (-127) (-127) (-127) (-127) (-127) (-127) (-127)
				(-127) (-127) (-127) (-127) (-127) (-127) (-127) (-127) (-127) (-127) (-127) (-127) (-127) (-127) (-127) (-127)
				(-127) (-127) (-127) (-127) (-127) (-127) (-127) (-127) (-127) (-127) (-127) (-127) (-127) (-127) (-127) (-127)
				(-127) (-127) (-127) (-127) (-127) (-127) (-127) (-127) (-127) (-127) (-127) (-127) (-127) (-127) (-127) (-127)
				(-127) (-127) (-127) (-127) (-127) (-127) (-127) (-127) (-127) (-127) (-127) (-127) (-127) (-127) (-127) (-127)
				(-127) (-127) (-127) (-127) (-127) (-127) (-127) (-127) (-127) (-127) (-127) (-127) (-127) (-127) (-127) (-127)
				(-127) (-127) (-127) (-127) (-127) (-127) (-127) (-127) (-127) (-127) (-127) (-127) (-127) (-127) (-127) (-127)
				(-127) (-127) (-127) (-127) (-127) (-127) (-127) (-127) (-127) (-127) (-127) (-127) (-127) (-127) (-127) (-127)
				(-127) (-127) (-127) (-127) (-127) (-127) (-127) (-127) (-127) (-127) (-127) (-127) (-127) (-127) (-127) (-127)
				(-127) (-127) (-127) (-127) (-127) (-127) (-127) (-127) (-127) (-127) (-127) (-127) (-127) (-127) (-127) (-127)
				(-127) (-127) (-127) (-127) (-127) (-127) (-127) (-127) (-127) (-127) (-127) (-127) (-127) (-127) (-127) (-127)
				(-127) (-127) (-127) (-127) (-127) (-127) (-127) (-127) (-127) (-127) (-127) (-127) (-127) (-127) (-127) (-127)
				(-127) (-127) (-127) (-127) (-127) (-127) (-127) (-127) (-127) (-127) (-127) (-127) (-127) (-127) (-127) (-127)
				(-127) (-127) (-127) (-127) (-127) (-127) (-127) (-127) (-127) (-127) (-127) (-127) (-127) (-127) (-127) (-127)
				(-127) (-127) (-127) (-127) (-127) (-127) (-127) (-127) (-127) (-127) (-127) (-127) (-127) (-127) (-127) (-127)
				(-127) (-127) (-127) (-127) (-127) (-127) (-127) (-127) (-127) (-127) (-127) (-127) (-127) (-127) (-127) (-127)
				(-127) (-127) (-127) (-127) (-127) (-127) (-127) (-127) (-127) (-127) (-127) (-127) (-127) (-127) (-127) (-127)
				(-127) (-127) (-127) (-127) (-127) (-127) (-127) (-127) (-127) (-127) (-127) (-127) (-127) (-127) (-127) (-127)
				(-127) (-127) (-127) (-127) (-127) (-127) (-127) (-127) (-127) (-127) (-127) (-127) (-127) (-127) (-127) (-127)
				(-127) (-127) (-127) (-127) (-127) (-127) (-127) (-127) (-127) (-127) (-127) (-127) (-127) (-127) (-127) (-127)
				(-127) (-127) (-127) (-127) (-127) (-127) (-127) (-127) (-127) (-127) (-127) (-127) (-127) (-127) (-127) (-127)
				(-127) (-127) (-127) (-127) (-127) (-127) (-127) (-127) (-127) (-127) (-127) (-127) (-127) (-127) (-127) (-127)
				(-127) (-127) (-127) (-127) (-127) (-127) (-127) (-127) (-127) (-127) (-127) (-127) (-127) (-127) (-127) (-127)
				(-127) (-127) (-127) (-127) (-127) (-127) (-127) (-127) (-127) (-127) (-127) (-127) (-127) (-127) (-127) (-127)
				(-127) (-127) (-127) (-127) (-127) (-127) (-127) (-127) (-127) (-127) (-127) (-127) (-127) (-127) (-127) (-127)
				(-127) (-127) (-127) (-127) (-127) (-127) (-127) (-127) (-127) (-127) (-127) (-127) (-127) (-127) (-127) (-127)
				(-127) (-127) (-127) (-127) (-127) (-127) (-127) (-127) (-127) (-127) (-127) (-127) (-127) (-127) (-127) (-127)
				(-127) (-127) (-127) (-127) (-127) (-127) (-127) (-127) (-127) (-127) (-127) (-127) (-127) (-127) (-127) (-127)
				(-127) (-127) (-127) (-127)>;

			PS_Config_Diff_Test_Frame = <50>;
		};
	};
};
